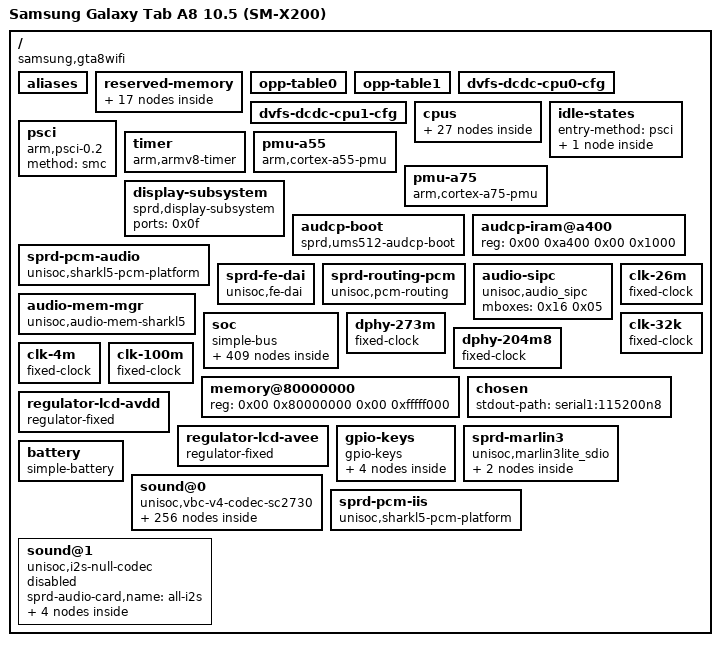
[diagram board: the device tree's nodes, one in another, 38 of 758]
/dts-v1/;

/ {
	interrupt-parent = <0x01>;
	#address-cells = <0x02>;
	#size-cells = <0x02>;
	model = "Samsung Galaxy Tab A8 10.5 (SM-X200)";
	compatible = "samsung,gta8wifi", "sprd,ums512-25c10", "sprd,ums512";
	sprd,sc-id = "ums512 wifionly 1000";

	aliases {
		mmc0 = "/soc/apb@70000000/mmc@1100000";
		mmc1 = "/soc/apb@70000000/mmc@1200000";
		mmc3 = "/soc/apb@70000000/mmc@1400000";
		i2c0 = "/soc/apb@70000000/i2c@300000";
		i2c1 = "/soc/apb@70000000/i2c@400000";
		i2c2 = "/soc/apb@70000000/i2c@500000";
		i2c3 = "/soc/apb@70000000/i2c@600000";
		i2c4 = "/soc/apb@70000000/i2c@700000";
		i2c7 = "/soc/bus@32000000/i2c@60000";
		serial0 = "/soc/apb@70000000/serial@0";
		serial1 = "/soc/apb@70000000/serial@100000";
		spi2 = "/soc/apb@70000000/spi@a00000";
	};

	reserved-memory {
		#address-cells = <0x02>;
		#size-cells = <0x02>;
		ranges;

		audio-mem@87400000 {
			reg = <0x00 0x87400000 0x00 0x400000>;
			no-map;
			phandle = <0x13>;
		};

		smem@88000000 {
			compatible = "shared-dma-pool";
			reg = <0x00 0x88000000 0x00 0x40000>;
			no-map;
			phandle = <0x19>;
		};

		pmsys@88040000 {
			reg = <0x00 0x88040000 0x00 0x2c0000>;
			no-map;
			phandle = <0x18>;
		};

		audiodsp-mem@89000000 {
			reg = <0x00 0x89000000 0x00 0x600000>;
			no-map;
			phandle = <0x12>;
		};

		ddrbist-mem@80000000 {
			reg = <0x00 0x80000000 0x00 0x1000>;
			no-map;
		};

		sysdumpinfo-mem@80001000 {
			reg = <0x00 0x80001000 0x00 0x1000>;
			no-map;
		};

		rebootescrow@81ff0000 {
			reg = <0x00 0x81ff0000 0x00 0x10000>;
			no-map;
		};

		/*
		 * Deduplicated audio-mem@87500000 (subset of audio-mem@87400000)
		 * and sp-ddr-mem@88000000 (union of smem@88000000 + pmsys@88040000).
		 * Reclaimed 196.47 MiB of unused Android carveouts:
		 *   cp-modem@89600000 (85 MiB), hole-mem@8f000000 (11 MiB),
		 *   faceid-mem@efaae000 (5 MiB), vdsp-mem@f09ae000 (55 MiB),
		 *   framebuffer-mem@fd708000 (30.35 MiB), writeback-mem@ff562000 (10.12 MiB).
		 * Validate zero bad pages with tools/ram-scan.py after booting!
		 */

		sipc-mem@87800000 {
			reg = <0x00 0x87800000 0x00 0x800000>;
			no-map;
		};

		sipc-ss-mem@88300000 {
			reg = <0x00 0x88300000 0x00 0x80000>;
			no-map;
		};

		sml-mem@94000000 {
			reg = <0x00 0x94000000 0x00 0x40000>;
			no-map;
		};

		tos-mem@94040000 {
			reg = <0x00 0x94040000 0x00 0x5fc0000>;
			no-map;
		};

		sh-mem@9a000000 {
			reg = <0x00 0x9a000000 0x00 0x100000>;
			no-map;
		};

		ramoops@fff80000 {
			compatible = "ramoops";
			reg = <0x00 0xfff80000 0x00 0x40000>;
			record-size = <0x8000>;
			console-size = <0x8000>;
			pmsg-size = <0x8000>;
			no-map;
		};

		debug-mem@100000000 {
			reg = <0x01 0x00 0x00 0x1000>;
			no-map;
		};

		framebuffer-region@9e000000 {
			compatible = "framebuffer";
			reg = <0x00 0x9e000000 0x00 0x8ca000>;
			iommu-addresses = <0x02 0x9e000000 0x8ca000>;
			no-map;
			phandle = <0xad>;
		};

		/*
		 * Stock wifionly overlay: drm_reserved (secure video). The TEE
		 * firewalls it: writes vanish, reads return zero (measured
		 * 2026-11-10, 0xe32ae000-0xee6adfff). Reserve stock's full size.
		 */
		drm-mem@e32ae000 {
			reg = <0x00 0xe32ae000 0x00 0xc800000>;
			no-map;
		};

		protected-mem@effae000 {
			reg = <0x00 0xeffae000 0x00 0x2000>;
			no-map;
		};
	};

	opp-table0 {
		sprd,hw-dvfs-device = <0x03>;
		cpufreq-cluster-cpumask = <0x3f>;
		transition_delay_us = <0x1f4>;
		operating-points = <0x96000 0xb8a1a 0xbb800 0xb8a1a 0xeadd0 0xb8a1a 0x1174c0 0xb8a1a 0x12c000 0xc042c 0x169d10 0xd59f8 0x177000 0xd9701 0x1a2f20 0xe8b25 0x1bc560 0xf1da1 0x1e8c50 0x100590>;
		phandle = <0x0c>;
	};

	opp-table1 {
		sprd,hw-dvfs-device = <0x03>;
		cpufreq-cluster-cpumask = <0xc0>;
		transition_delay_us = <0x1f4>;
		operating-points = <0x12c000 0xb71b0 0x169d10 0xcf850 0x177000 0xd4670 0x1a94b0 0xe7ef0 0x1c9080 0xf4240 0x1e8c50 0x100590>;
		phandle = <0x0e>;
	};

	dvfs-dcdc-cpu0-cfg {
		pmic-type-num = <0x00>;
		slew-rate = <0x249f>;
		tuning-latency-us = <0x00>;
		phandle = <0x22>;
	};

	dvfs-dcdc-cpu1-cfg {
		third-pmic-used;
		chnl-i2c-used;
		pmic-type-num = <0x02>;
		slew-rate = <0xfa0>;
		tuning-latency-us = <0x00>;
		phandle = <0x23>;
	};

	cpus {
		#address-cells = <0x02>;
		#size-cells = <0x00>;

		cpu-map {

			cluster0 {

				core0 {
					cpu = <0x04>;
				};

				core1 {
					cpu = <0x05>;
				};

				core2 {
					cpu = <0x06>;
				};

				core3 {
					cpu = <0x07>;
				};

				core4 {
					cpu = <0x08>;
				};

				core5 {
					cpu = <0x09>;
				};
			};

			cluster1 {

				core0 {
					cpu = <0x0a>;
				};

				core1 {
					cpu = <0x0b>;
				};
			};
		};

		cpu@0 {
			device_type = "cpu";
			compatible = "arm,cortex-a55";
			reg = <0x00 0x00>;
			cpufreq-data-v1 = <0x0c>;
			enable-method = "psci";
			cpu-idle-states = <0x0d>;
			clock-frequency = <0x6c7aff00>;
			capacity-dmips-mhz = <0x220>;
			dynamic-power-coefficient = <0x66>;
			#cooling-cells = <0x02>;
			phandle = <0x04>;

			thermal-idle {
				#cooling-cells = <0x02>;
				duration-us = <0x2710>;
				exit-latency-us = <0xfa0>;
			};
		};

		cpu@100 {
			device_type = "cpu";
			compatible = "arm,cortex-a55";
			reg = <0x00 0x100>;
			cpufreq-data-v1 = <0x0c>;
			enable-method = "psci";
			cpu-idle-states = <0x0d>;
			clock-frequency = <0x6c7aff00>;
			capacity-dmips-mhz = <0x220>;
			dynamic-power-coefficient = <0x66>;
			#cooling-cells = <0x02>;
			phandle = <0x05>;

			thermal-idle {
				#cooling-cells = <0x02>;
				duration-us = <0x2710>;
				exit-latency-us = <0xfa0>;
			};
		};

		cpu@200 {
			device_type = "cpu";
			compatible = "arm,cortex-a55";
			reg = <0x00 0x200>;
			cpufreq-data-v1 = <0x0c>;
			enable-method = "psci";
			cpu-idle-states = <0x0d>;
			clock-frequency = <0x6c7aff00>;
			capacity-dmips-mhz = <0x220>;
			dynamic-power-coefficient = <0x66>;
			#cooling-cells = <0x02>;
			phandle = <0x06>;

			thermal-idle {
				#cooling-cells = <0x02>;
				duration-us = <0x2710>;
				exit-latency-us = <0xfa0>;
			};
		};

		cpu@300 {
			device_type = "cpu";
			compatible = "arm,cortex-a55";
			reg = <0x00 0x300>;
			cpufreq-data-v1 = <0x0c>;
			enable-method = "psci";
			cpu-idle-states = <0x0d>;
			clock-frequency = <0x6c7aff00>;
			capacity-dmips-mhz = <0x220>;
			dynamic-power-coefficient = <0x66>;
			#cooling-cells = <0x02>;
			phandle = <0x07>;

			thermal-idle {
				#cooling-cells = <0x02>;
				duration-us = <0x2710>;
				exit-latency-us = <0xfa0>;
			};
		};

		cpu@400 {
			device_type = "cpu";
			compatible = "arm,cortex-a55";
			reg = <0x00 0x400>;
			cpufreq-data-v1 = <0x0c>;
			enable-method = "psci";
			cpu-idle-states = <0x0d>;
			clock-frequency = <0x6c7aff00>;
			capacity-dmips-mhz = <0x220>;
			dynamic-power-coefficient = <0x66>;
			#cooling-cells = <0x02>;
			phandle = <0x08>;

			thermal-idle {
				#cooling-cells = <0x02>;
				duration-us = <0x2710>;
				exit-latency-us = <0xfa0>;
			};
		};

		cpu@500 {
			device_type = "cpu";
			compatible = "arm,cortex-a55";
			reg = <0x00 0x500>;
			cpufreq-data-v1 = <0x0c>;
			enable-method = "psci";
			cpu-idle-states = <0x0d>;
			clock-frequency = <0x6c7aff00>;
			capacity-dmips-mhz = <0x220>;
			dynamic-power-coefficient = <0x66>;
			#cooling-cells = <0x02>;
			phandle = <0x09>;

			thermal-idle {
				#cooling-cells = <0x02>;
				duration-us = <0x2710>;
				exit-latency-us = <0xfa0>;
			};
		};

		cpu@600 {
			device_type = "cpu";
			compatible = "arm,cortex-a75";
			reg = <0x00 0x600>;
			cpufreq-data-v1 = <0x0e>;
			enable-method = "psci";
			cpu-idle-states = <0x0d>;
			clock-frequency = <0x6c7aff00>;
			capacity-dmips-mhz = <0x400>;
			dynamic-power-coefficient = <0x1f5>;
			#cooling-cells = <0x02>;
			phandle = <0x0a>;

			thermal-idle {
				#cooling-cells = <0x02>;
				duration-us = <0x2710>;
				exit-latency-us = <0xfa0>;
			};
		};

		cpu@700 {
			device_type = "cpu";
			compatible = "arm,cortex-a75";
			reg = <0x00 0x700>;
			cpufreq-data-v1 = <0x0e>;
			enable-method = "psci";
			cpu-idle-states = <0x0d>;
			clock-frequency = <0x6c7aff00>;
			capacity-dmips-mhz = <0x400>;
			dynamic-power-coefficient = <0x1f5>;
			#cooling-cells = <0x02>;
			phandle = <0x0b>;

			thermal-idle {
				#cooling-cells = <0x02>;
				duration-us = <0x2710>;
				exit-latency-us = <0xfa0>;
			};
		};
	};

	idle-states {
		entry-method = "psci";

		cpu-pd {
			compatible = "arm,idle-state";
			entry-latency-us = <0xfa0>;
			exit-latency-us = <0xfa0>;
			min-residency-us = <0x2710>;
			local-timer-stop;
			arm,psci-suspend-param = <0x10000>;
			phandle = <0x0d>;
		};
	};

	psci {
		compatible = "arm,psci-0.2";
		method = "smc";
	};

	timer {
		compatible = "arm,armv8-timer";
		interrupts = <0x01 0x0d 0x04 0x01 0x0e 0x04 0x01 0x0b 0x04 0x01 0x0a 0x04>;
	};

	pmu-a55 {
		compatible = "arm,cortex-a55-pmu";
		interrupts = <0x00 0x70 0x04 0x00 0x71 0x04 0x00 0x72 0x04 0x00 0x73 0x04 0x00 0x74 0x04 0x00 0x75 0x04>;
		interrupt-affinity = <0x04 0x05 0x06 0x07 0x08 0x09>;
	};

	pmu-a75 {
		compatible = "arm,cortex-a75-pmu";
		interrupts = <0x00 0x76 0x04 0x00 0x77 0x04>;
		interrupt-affinity = <0x0a 0x0b>;
	};

	display-subsystem {
		compatible = "sprd,display-subsystem";
		ports = <0x0f>;
		status = "okay";
	};

	audcp-boot {
		compatible = "sprd,ums512-audcp-boot";
		dsp-reboot-mode = <0x00>;
		sysshutdown = <0x10 0x60 0x2000000>;
		coreshutdown = <0x10 0x5c 0x1000000>;
		deepsleep = <0x10 0xcc 0x80000>;
		corereset = <0x10 0xb0 0x400>;
		sysreset = <0x10 0xb0 0x200>;
		reset_sel = <0x10 0x7a4 0xff>;
		sysstatus = <0x10 0xb8 0xff000000>;
		corestatus = <0x10 0x10c 0xff>;
		sleepstatus = <0x10 0xd4 0xf000>;
		bootprotect = <0x11 0x78 0xffff>;
		bootvector = <0x11 0x140 0xffffffff>;
		bootaddress_sel = <0x11 0x144 0x01>;
		accessenable = <0x11 0x14c 0x20>;
		memory-region = <0x12 0x13>;
		sprd,audcp-aon-iram = <0x14>;
		#power-domain-cells = <0x00>;
		status = "okay";
		phandle = <0x36>;
	};

	audcp-iram@a400 {
		reg = <0x00 0xa400 0x00 0x1000>;
		phandle = <0x14>;
	};

	sprd-pcm-audio {
		compatible = "unisoc,sharkl5-pcm-platform", "unisoc,sharkl5pro-pcm-platform";
		#sound-dai-cells = <0x00>;
		dmas = <0x15 0x01 0x15 0x02 0x15 0x03 0x15 0x04 0x15 0x11 0x15 0x12 0x15 0x0f 0x15 0x10 0x15 0x0e 0x15 0x08 0x15 0x0c 0x15 0x09 0x15 0x0d 0x15 0x08 0x15 0x0b 0x15 0x06 0x15 0x0e 0x15 0x0e 0x15 0x0c 0x15 0x06 0x15 0x07 0x15 0x14>;
		dma-names = "normal_p_l", "normal_p_r", "normal_c_l", "normal_c_r", "normal23_p_l", "normal23_p_r", "normal23_c_l", "normal23_c_r", "dspcap_c", "a2dppcm_p", "voice_c", "fast_p", "loop_c", "loop_p", "voip_c", "voip_p", "dspfmcap_c", "dspbtscocap_c", "recognise_c", "voice_pcm_p", "hifi_p", "hifi_fast_p";
		phandle = <0xbb>;
	};

	sprd-fe-dai {
		compatible = "unisoc,fe-dai";
		#sound-dai-cells = <0x01>;
		phandle = <0xbc>;
	};

	sprd-routing-pcm {
		compatible = "unisoc,pcm-routing";
		#sound-dai-cells = <0x00>;
		phandle = <0xbd>;
	};

	audio-sipc {
		compatible = "unisoc,audio_sipc";
		mboxes = <0x16 0x05>;
	};

	audio-mem-mgr {
		compatible = "unisoc,audio-mem-sharkl5", "unisoc,audio-mem-sharkl5pro";
		memory-region = <0x13 0x12>;
		ddr32-ap-dsp-map-offset = <0x00>;
		sprd,ddr32-dma = <0x87400000 0x300000>;
		sprd,ddr32-dspmemdump = <0x87700000 0x80000>;
		sprd,cmdaddr = <0x87780000 0x400>;
		sprd,smsg-addr = <0x87780400 0xa10>;
		sprd,shmaddr-aud-str = <0x87780e10 0x400>;
		sprd,shmaddr-dsp-vbc = <0x87781210 0x1400>;
		sprd,shmaddr-nxp = <0x87782610 0x400>;
		sprd,shmaddr-dsp-smartpa = <0x87782a10 0x1000>;
		sprd,shmaddr-reg-dump = <0x87783a10 0x400>;
		sprd,iram-ap-base = <0x33800000>;
		sprd,iram-dsp-base = <0x1800000>;
		sprd,offload-addr = <0x33800000 0x5c00>;
		sprd,normal-captue-linklilst-node1 = <0x33805e00 0x200>;
		sprd,normal-captue-data = <0x33806000 0x1e00>;
		sprd,normal-captue-linklilst-node2 = <0x33807e00 0x200>;
		sprd,audcp-aon-iram = <0x14>;
	};

	soc {
		compatible = "simple-bus";
		#address-cells = <0x02>;
		#size-cells = <0x02>;
		ranges;

		pmsys@800000 {
			compatible = "sprd,ums512-pmsys";
			/*
			 * LK 0x9f00c880 contract: sprd,name="pmic" + child cproc,name="pm_sys".
			 * Keep disabled until Trusty TA com.android.trusty.kernelbootcp
			 * (/dev/trusty-ipc-dev0) is wired: TrustOS locks AON_APB 0x327d008c
			 * (SP CM4 core reset) against non-secure EL1 writes.
			 */
			sprd,name = "pmic";
			status = "disabled";
			reg = <0x00 0x800000 0x00 0x1000>;
			dma-ranges = <0x18000000 0x00 0x88000000 0x8000000>;
			#address-cells = <0x01>;
			#size-cells = <0x01>;
			ranges = <0x88040000 0x00 0x88040000 0x200000>;
			sprd,syscon-aon-apb = <0x11>;
			sprd,syscon-pmu-apb = <0x10>;
			resets = <0x17 0x08>;
			memory-region = <0x18>;
			firmware-name = "sprd/pm_bootcode.bin", "sprd/pm_sys.bin";

			pm-sys@88040000 {
				cproc,name = "pm_sys";
				reg = <0x88040000 0x200000>;
			};

			sipc {
				#address-cells = <0x01>;
				#size-cells = <0x00>;
				label = "pmsys";
				mboxes = <0x16 0x01 0x16 0x06>;
				memory-region = <0x19>;

				channel@4 {
					reg = <0x04>;
					sprd,channel-type = "sbuf";
					sprd,channel-name = "pm_shub";
					#address-cells = <0x01>;
					#size-cells = <0x01>;
					sprd,num-buffers = <0x02>;
					sprd,tx-buf-size = <0x800>;
					sprd,rx-buf-size = <0xb00>;

					rpmsg@0 {
						compatible = "samsung,sprd-shub";
						reg = <0x00 0x00>;
						sprd,channel-name = "shub_main";
					};

					rpmsg@1 {
						compatible = "samsung,sprd-shub";
						reg = <0x01 0x01>;
						sprd,channel-name = "shub_nowakeup";
					};
				};

				channel@5 {
					reg = <0x05>;
					sprd,channel-type = "sbuf";
					sprd,channel-name = "slog_pm";
					#address-cells = <0x01>;
					#size-cells = <0x01>;
					sprd,tx-buf-size = <0x00>;
					sprd,rx-buf-size = <0x500>;

					rpmsg@0 {
						reg = <0x00 0x00>;
						sprd,channel-name = "slog_pm";
					};
				};

				channel@6 {
					reg = <0x06>;
					sprd,channel-type = "sbuf";
					sprd,channel-name = "sctl_pm";
					#address-cells = <0x01>;
					#size-cells = <0x01>;
					sprd,tx-buf-size = <0x20>;
					sprd,rx-buf-size = <0x40>;

					rpmsg@0 {
						reg = <0x00 0x00>;
						sprd,channel-name = "sctl_pm";
					};
				};

				channel@29 {
					reg = <0x29>;
					sprd,channel-type = "sbuf";
					sprd,channel-name = "stime_pm";
					#address-cells = <0x01>;
					#size-cells = <0x01>;
					sprd,tx-buf-size = <0x80>;
					sprd,rx-buf-size = <0x40>;

					rpmsg@0 {
						reg = <0x00 0x00>;
						sprd,channel-name = "stime_pm";
					};
				};

				channel@16 {
					reg = <0x16>;
					sprd,channel-type = "dfs";
					sprd,channel-name = "pm_ctrl";
				};
			};
		};

		interrupt-controller@12000000 {
			compatible = "arm,gic-v3";
			reg = <0x00 0x12000000 0x00 0x20000 0x00 0x12040000 0x00 0x100000>;
			#interrupt-cells = <0x03>;
			#address-cells = <0x02>;
			#size-cells = <0x02>;
			ranges;
			redistributor-stride = <0x00 0x20000>;
			#redistributor-regions = <0x01>;
			interrupt-controller;
			interrupts = <0x01 0x09 0x04>;
			phandle = <0x01>;
		};

		syscon@20100000 {
			compatible = "sprd,ums512-glbregs", "syscon", "simple-mfd";
			reg = <0x00 0x20100000 0x00 0x4000>;
			#address-cells = <0x01>;
			#size-cells = <0x01>;
			ranges = <0x00 0x00 0x20100000 0x4000>;
			phandle = <0xae>;

			clock-controller@0 {
				compatible = "sprd,ums512-apahb-gate";
				reg = <0x00 0x3000>;
				clocks = <0x1a>;
				clock-names = "ext-26m";
				#clock-cells = <0x01>;
				phandle = <0x48>;
			};
		};

		syscon@31050000 {
			compatible = "sprd,ums512-glbregs", "syscon", "simple-mfd";
			reg = <0x00 0x31050000 0x00 0x9000>;
		};

		efuse@32240000 {
			compatible = "sprd,ums312-efuse";
			reg = <0x00 0x32240000 0x00 0x10000>;
			clock-names = "enable";
			clocks = <0x1b 0x10>;
			hwlocks = <0x1c 0x08>;

			nvmem-layout {
				compatible = "fixed-layout";
				#address-cells = <0x01>;
				#size-cells = <0x01>;

				uid-start@5c {
					reg = <0x5c 0x04>;
					phandle = <0xb9>;
				};

				uid-end@58 {
					reg = <0x58 0x04>;
					phandle = <0xba>;
				};

				thm0-sign@38 {
					reg = <0x38 0x01>;
					bits = <0x00 0x01>;
					phandle = <0x8a>;
				};

				thm0-ratio@38 {
					reg = <0x38 0x01>;
					bits = <0x01 0x07>;
					phandle = <0x8b>;
				};

				thm0-sen0@39 {
					reg = <0x39 0x01>;
					bits = <0x00 0x08>;
					phandle = <0x8c>;
				};

				thm0-sen1@41 {
					reg = <0x41 0x01>;
					bits = <0x00 0x08>;
					phandle = <0x8d>;
				};

				thm0-sen2@40 {
					reg = <0x40 0x01>;
					bits = <0x00 0x08>;
					phandle = <0x8e>;
				};

				thm0-sen3@43 {
					reg = <0x43 0x01>;
					bits = <0x00 0x08>;
					phandle = <0x8f>;
				};

				thm0-sen4@42 {
					reg = <0x42 0x01>;
					bits = <0x00 0x08>;
					phandle = <0x90>;
				};

				thm1-sign@3c {
					reg = <0x3c 0x01>;
					bits = <0x00 0x01>;
					phandle = <0x91>;
				};

				thm1-ratio@3c {
					reg = <0x3c 0x01>;
					bits = <0x01 0x07>;
					phandle = <0x92>;
				};

				thm1-sen0@3d {
					reg = <0x3d 0x01>;
					bits = <0x00 0x08>;
					phandle = <0x93>;
				};

				thm1-sen1@2f {
					reg = <0x2f 0x01>;
					bits = <0x00 0x08>;
					phandle = <0x94>;
				};

				thm1-sen2@2e {
					reg = <0x2e 0x01>;
					bits = <0x00 0x08>;
					phandle = <0x95>;
				};

				thm1-sen3@29 {
					reg = <0x29 0x01>;
					bits = <0x00 0x08>;
					phandle = <0x96>;
				};

				thm1-sen4@28 {
					reg = <0x28 0x01>;
					bits = <0x00 0x08>;
					phandle = <0x97>;
				};

				thm1-sen5@2b {
					reg = <0x2b 0x01>;
					bits = <0x00 0x08>;
					phandle = <0x98>;
				};

				thm2-sign@3e {
					reg = <0x3e 0x01>;
					bits = <0x00 0x01>;
					phandle = <0x99>;
				};

				thm2-ratio@3e {
					reg = <0x3e 0x01>;
					bits = <0x01 0x07>;
					phandle = <0x9a>;
				};

				thm2-sen0@3f {
					reg = <0x3f 0x01>;
					bits = <0x00 0x08>;
					phandle = <0x9b>;
				};
			};
		};

		syscon@322a0000 {
			compatible = "sprd,sharkl5pro-topdvfs-dev", "sprd,topdvfs-dev", "sprd,sharkl5pro-topdvfs", "sprd,ums512-glbregs", "syscon";
			reg = <0x00 0x322a0000 0x00 0x8000>;
			sprd,syscon-enable = <0x11>;
			module-enable-cfg = <0x04 0x07>;
			sprd,topdvfs-sysctrl = <0x1d>;
			cpu-dcdc-cells = <0x1e 0x1f>;
			device-dcdc-cells = <0x20 0x21>;
			phandle = <0x1d>;

			dcdc-cpu0 {
				dcdc-cpu-dvfs-cfg = <0x22>;
				phandle = <0x1e>;
			};

			dcdc-cpu1 {
				dcdc-cpu-dvfs-cfg = <0x23>;
				phandle = <0x1f>;
			};

			dcdc-mm {
				dcdc-dvfs-enable = <0x18 0x14 0x01>;
				dcdc-judge-vol-sw = <0x18 0x01 0x07 0x02>;
				dcdc-subsys-cells = <0x24 0x25 0x26>;
				phandle = <0x20>;

				audcp-sys {
					dcdc-subsys-tune-enable = <0x150 0x05 0x00>;
					phandle = <0x24>;
				};

				gpu-sys {
					dcdc-subsys-tune-enable = <0x150 0x01 0x01>;
					phandle = <0x25>;
				};

				mm-sys {
					dcdc-subsys-tune-enable = <0x150 0x02 0x00>;
					phandle = <0x26>;
				};
			};

			dcdc-modem {
				dcdc-dvfs-enable = <0x3c 0x14 0x01>;
				dcdc-judge-vol-sw = <0x3c 0x01 0x07 0x02>;
				dcdc-subsys-cells = <0x27 0x28 0x29>;
				phandle = <0x21>;

				pubcp-sys {
					dcdc-subsys-tune-enable = <0x150 0x04 0x00>;
					phandle = <0x27>;
				};

				wtlcp-sys {
					dcdc-subsys-tune-enable = <0x150 0x03 0x00>;
					phandle = <0x28>;
				};

				ap-sys {
					dcdc-subsys-tune-enable = <0x150 0x00 0x01>;
					phandle = <0x29>;
				};
			};
		};

		hardware-dvfs-platform {
			compatible = "sprd,hardware-cpufreq";
		};

		cpudvfs-dev@322a8000 {
			compatible = "sprd,sharkl5pro-cpudvfs";
			reg = <0x00 0x322a8000 0x00 0x1000>;
			enable-syscon = <0x11 0x04 0x80>;
			topdvfs-controller = <0x1d>;
			host-cluster-cells = <0x2a 0x2b>;
			slave-cluster-cells = <0x2c 0x2d 0x2e>;
			mpll-cells = <0x2f 0x30 0x31>;
			status = "okay";
			phandle = <0x03>;

			lit-core-cluster {
				belong-dcdc-cell = <0x00>;
				lit_core_cluster_tbl = <0x00 0x00 0x00 0x00 0x00 0x00 0x00 0x01 0x01 0x00 0x01 0x01 0x01 0x00 0x02 0x01 0x00 0x02 0x01 0x01 0x00 0x03 0x00 0x00 0x02 0x01 0x01 0x00 0x03 0x00 0x00 0x03 0x01 0x01 0x01 0x01 0x00 0x01 0x04 0x01 0x01 0x00 0x03 0x00 0x02 0x05 0x04 0x04 0x02 0x02 0x00 0x03 0x06 0x04 0x04 0x00 0x03 0x00 0x04 0x07 0x04 0x05 0x03 0x03 0x00 0x05 0x08 0x04 0x05 0x04 0x03 0x00 0x06 0x09 0x05 0x05 0x05>;
				phandle = <0x2a>;
			};

			big-core-cluster {
				belong-dcdc-cell = <0x01>;
				big_core_cluster_tbl = <0x00 0x00 0x00 0x00 0x00 0x00 0x00 0x01 0x00 0x00 0x03 0x01 0x01 0x00 0x03 0x00 0x01 0x05 0x04 0x04 0x00 0x02 0x00 0x02 0x06 0x04 0x04 0x00 0x03 0x00 0x03 0x07 0x04 0x05 0x01 0x03 0x00 0x04 0x08 0x04 0x05 0x03 0x03 0x00 0x05 0x09 0x05 0x05 0x04>;
				phandle = <0x2b>;
			};

			scu-cluster {
				belong-dcdc-cell = <0x00>;
				scu_cluster_tbl = <0x00 0x00 0x00 0x00 0x00 0x03 0x00 0x00 0x01 0x00 0x03 0x00 0x00 0x01 0x01 0x01 0x00 0x00 0x01 0x00 0x03 0x00 0x01 0x01 0x02 0x03 0x00 0x02 0x01 0x03 0x03 0x00 0x03 0x01 0x04 0x03 0x00 0x04 0x01 0x05 0x03 0x00 0x05 0x01 0x06 0x03 0x00 0x06 0x01 0x07>;
				phandle = <0x2c>;
			};

			periph-cluster {
				belong-dcdc-cell = <0x00>;
				periph_cluster_tbl = <0x00 0x00 0x00 0x01 0x00 0x00 0x02 0x01 0x02 0x03 0x01 0x02 0x02 0x00 0x02 0x03 0x00 0x06>;
				phandle = <0x2d>;
			};

			gic-cluster {
				belong-dcdc-cell = <0x00>;
				gic_cluster_tbl = <0x00 0x00 0x00 0x01 0x00 0x00 0x02 0x01 0x02 0x03 0x01 0x02 0x02 0x00 0x02 0x03 0x00 0x02>;
				phandle = <0x2e>;
			};

			mpll-ananke {
				mpll-sel-syscon = <0x32 0x98 0xd0>;
				phandle = <0x2f>;
			};

			mpll-prometheus {
				mpll-sel-syscon = <0x33 0x44 0xd0>;
				phandle = <0x30>;
			};

			mpll-scu {
				mpll-sel-syscon = <0x32 0xdc 0x68>;
				phandle = <0x31>;
			};
		};

		syscon@32310000 {
			compatible = "sprd,ums512-glbregs", "syscon", "simple-mfd";
			reg = <0x00 0x32310000 0x00 0x1000>;
		};

		syscon@32320000 {
			compatible = "sprd,ums512-glbregs", "syscon", "simple-mfd";
			reg = <0x00 0x32320000 0x00 0x1000>;
		};

		syscon@32330000 {
			compatible = "sprd,ums512-glbregs", "syscon", "simple-mfd";
			reg = <0x00 0x32330000 0x00 0x1000>;
		};

		syscon@32340000 {
			compatible = "sprd,ums512-glbregs", "syscon", "simple-mfd";
			reg = <0x00 0x32340000 0x00 0x1000>;
		};

		syscon@32350000 {
			compatible = "sprd,ums512-glbregs", "syscon", "simple-mfd";
			reg = <0x00 0x32350000 0x00 0x1000>;
		};

		syscon@32360000 {
			compatible = "sprd,ums512-glbregs", "syscon", "simple-mfd";
			reg = <0x00 0x32360000 0x00 0x1000>;
		};

		syscon@32390000 {
			compatible = "sprd,ums512-glbregs", "syscon", "simple-mfd";
			reg = <0x00 0x32390000 0x00 0x3000>;
			#address-cells = <0x01>;
			#size-cells = <0x01>;
			ranges = <0x00 0x00 0x32390000 0x3000>;

			clock-controller@0 {
				compatible = "sprd,ums512-g0-pll";
				reg = <0x00 0x100>;
				#clock-cells = <0x01>;
			};
		};

		syscon@323b0000 {
			compatible = "sprd,ums512-glbregs", "syscon", "simple-mfd";
			reg = <0x00 0x323b0000 0x00 0x3000>;
			#address-cells = <0x01>;
			#size-cells = <0x01>;
			ranges = <0x00 0x00 0x323b0000 0x3000>;
			phandle = <0x33>;

			clock-controller@0 {
				compatible = "sprd,ums512-g2-pll";
				reg = <0x00 0x100>;
				#clock-cells = <0x01>;
			};

			phy@100 {
				compatible = "sprd,ums512-hsphy";
				reg = <0x100 0x2000>;
				sprd,syscon-aon-apb = <0x11>;
				#phy-cells = <0x00>;
				status = "okay";
				phy-supply = <0x34>;
				phandle = <0x9c>;
			};
		};

		syscon@323c0000 {
			compatible = "sprd,ums512-glbregs", "syscon", "simple-mfd";
			reg = <0x00 0x323c0000 0x00 0x3000>;
			#address-cells = <0x01>;
			#size-cells = <0x01>;
			ranges = <0x00 0x00 0x323c0000 0x3000>;
			phandle = <0x32>;

			clock-controller@0 {
				compatible = "sprd,ums512-g3-pll";
				reg = <0x00 0x3000>;
				clocks = <0x1a>;
				clock-names = "ext-26m";
				#clock-cells = <0x01>;
				phandle = <0x72>;
			};
		};

		syscon@323e0000 {
			compatible = "sprd,ums512-glbregs", "syscon", "simple-mfd";
			reg = <0x00 0x323e0000 0x00 0x3000>;
			#address-cells = <0x01>;
			#size-cells = <0x01>;
			ranges = <0x00 0x00 0x323e0000 0x3000>;

			clock-controller@0 {
				compatible = "sprd,ums512-gc-pll";
				reg = <0x00 0x100>;
				clocks = <0x1a>;
				clock-names = "ext-26m";
				#clock-cells = <0x01>;
				phandle = <0x45>;
			};
		};

		syscon@323f0000 {
			compatible = "sprd,ums512-glbregs", "syscon", "simple-mfd";
			reg = <0x00 0x323f0000 0x00 0x3000>;
		};

		syscon@327d0000 {
			compatible = "sprd,ums512-glbregs", "syscon", "simple-mfd";
			reg = <0x00 0x327d0000 0x00 0x3000>;
			#address-cells = <0x01>;
			#size-cells = <0x01>;
			ranges = <0x00 0x00 0x327d0000 0x3000>;
			phandle = <0x11>;

			clock-controller@0 {
				compatible = "sprd,ums512-aon-gate";
				reg = <0x00 0x3000>;
				clocks = <0x1a>;
				clock-names = "ext-26m";
				#clock-cells = <0x01>;
				phandle = <0x1b>;
			};
		};

		syscon@327e0000 {
			compatible = "sprd,ums512-glbregs", "syscon", "simple-mfd";
			reg = <0x00 0x327e0000 0x00 0x3000>;
			#address-cells = <0x01>;
			#size-cells = <0x01>;
			ranges = <0x00 0x00 0x327e0000 0x3000>;
			phandle = <0x10>;

			clock-controller@0 {
				compatible = "sprd,ums512-pmu-gate";
				reg = <0x00 0x3000>;
				clocks = <0x1a>;
				clock-names = "ext-26m";
				#clock-cells = <0x01>;
				#reset-cells = <0x01>;
				phandle = <0x17>;
			};

			power-controller {
				compatible = "sprd,ums512-power-controller";
				#address-cells = <0x01>;
				#size-cells = <0x00>;
				#power-domain-cells = <0x01>;
				phandle = <0x43>;

				power-domain@10 {
					reg = <0x0a>;
					clocks = <0x1b 0x08>;
					#power-domain-cells = <0x00>;
				};

				power-domain@13 {
					reg = <0x0d>;
					clocks = <0x1b 0x07>;
					#power-domain-cells = <0x00>;
				};

				power-domain@24 {
					reg = <0x18>;
					#power-domain-cells = <0x00>;
				};
			};
		};

		gpio@32000000 {
			compatible = "sprd,sharkl5pro-eic-debounce", "sprd,sc9860-eic-debounce";
			reg = <0x00 0x32020000 0x00 0x80 0x00 0x32030000 0x00 0x80 0x00 0x32230000 0x00 0x80 0x00 0x32270000 0x00 0x80>;
			gpio-controller;
			#gpio-cells = <0x02>;
			interrupt-controller;
			#interrupt-cells = <0x02>;
			interrupts = <0x00 0x48 0x04>;
		};

		gpio@32000080 {
			compatible = "sprd,sharkl5pro-eic-latch", "sprd,sc9860-eic-latch";
			reg = <0x00 0x32020080 0x00 0x20 0x00 0x32030080 0x00 0x20 0x00 0x32230080 0x00 0x20 0x00 0x32270080 0x00 0x20>;
			gpio-controller;
			#gpio-cells = <0x02>;
			interrupt-controller;
			#interrupt-cells = <0x02>;
			interrupts = <0x00 0x48 0x04>;
		};

		gpio@320000a0 {
			compatible = "sprd,sharkl5pro-eic-async", "sprd,sc9860-eic-async";
			reg = <0x00 0x320200a0 0x00 0x20 0x00 0x320300a0 0x00 0x20 0x00 0x322300a0 0x00 0x20 0x00 0x322700a0 0x00 0x20>;
			gpio-controller;
			#gpio-cells = <0x02>;
			interrupt-controller;
			#interrupt-cells = <0x02>;
			interrupts = <0x00 0x48 0x04>;
			phandle = <0xc8>;
		};

		gpio@320000c0 {
			compatible = "sprd,sharkl5pro-eic-sync", "sprd,sc9860-eic-sync";
			reg = <0x00 0x320200c0 0x00 0x20 0x00 0x320300c0 0x00 0x20 0x00 0x322300c0 0x00 0x20 0x00 0x322700c0 0x00 0x20>;
			gpio-controller;
			#gpio-cells = <0x02>;
			interrupt-controller;
			#interrupt-cells = <0x02>;
			interrupts = <0x00 0x48 0x04>;
			phandle = <0x73>;
		};

		syscon@3350d000 {
			compatible = "sprd,ums512-glbregs", "syscon", "simple-mfd";
			reg = <0x00 0x3350d000 0x00 0x1000>;
			#address-cells = <0x01>;
			#size-cells = <0x01>;
			ranges = <0x00 0x00 0x3350d000 0x1000>;

			clock-controller@0 {
				compatible = "sprd,ums512-audcpapb-gate";
				reg = <0x00 0x300>;
				#clock-cells = <0x01>;
			};
		};

		syscon@335e0000 {
			compatible = "sprd,ums512-glbregs", "syscon", "simple-mfd";
			reg = <0x00 0x335e0000 0x00 0x1000>;
			#address-cells = <0x01>;
			#size-cells = <0x01>;
			ranges = <0x00 0x00 0x335e0000 0x1000>;
			phandle = <0x35>;

			clock-controller@0 {
				compatible = "sprd,ums512-audcpahb-gate";
				reg = <0x00 0x300>;
				#clock-cells = <0x01>;
				phandle = <0x42>;
			};
		};

		mailbox@320a0000 {
			compatible = "sprd,ums512-mailbox";
			reg = <0x00 0x320a0000 0x00 0x8000 0x00 0x320a8000 0x00 0x8000>;
			clocks = <0x1b 0x12>;
			clock-names = "enable";
			interrupts = <0x00 0x52 0x04 0x00 0x53 0x04 0x00 0x54 0x04>;
			interrupt-names = "inbox", "outbox", "supp-outbox";
			#mbox-cells = <0x01>;
			status = "okay";
			phandle = <0x16>;
		};

		agcp {
			compatible = "simple-bus";
			#address-cells = <0x02>;
			#size-cells = <0x02>;
			ranges;

			vbc@33480000 {
				compatible = "unisoc,sharkl5-vbc", "unisoc,sharkl5pro-vbc";
				#sound-dai-cells = <0x01>;
				reg = <0x00 0x33480000 0x00 0x1000>;
				sprd,syscon-agcp-ahb = <0x35>;
				sprd,vbc-phy-offset = <0x32000000>;
				power-domains = <0x36>;
				pinctrl-names = "vbc_iis3_0", "vbc_iism0_0", "vbc_iis_to_pad", "vbc_iis_to_aon_usb", "vbc_iism0_1", "vbc_iism0_3", "vbc_iis0_3", "vbc_iis1_3", "vbc_iis2_3", "vbc_iis3_3", "ap_iis0_3";
				pinctrl-0 = <0x37>;
				pinctrl-1 = <0x38>;
				pinctrl-2 = <0x39>;
				pinctrl-3 = <0x3a>;
				pinctrl-4 = <0x3b>;
				pinctrl-5 = <0x3c>;
				pinctrl-6 = <0x3d>;
				pinctrl-7 = <0x3e>;
				pinctrl-8 = <0x3f>;
				pinctrl-9 = <0x40>;
				pinctrl-10 = <0x41>;
				phandle = <0xbe>;
			};

			mcdt@33490000 {
				compatible = "unisoc,sharkl5-mcdt", "unisoc,sharkl5pro-mcdt";
				reg = <0x00 0x33490000 0x00 0x170>;
				interrupts = <0x00 0xb6 0x04>;
				power-domains = <0x36>;
				sprd,ap-addr-offset = <0x32000000>;
				sprd,syscon-agcp-ahb = <0x35>;
			};

			dma-controller@33580000 {
				compatible = "sprd,sharkl5pro-dma", "sprd,sc9860-dma";
				reg = <0x00 0x33580000 0x00 0x4000>;
				interrupts = <0x00 0xb5 0x04>;
				power-domains = <0x36>;
				#dma-cells = <0x01>;
				dma-channels = <0x20>;
				clock-names = "enable", "ashb_eb";
				clocks = <0x42 0x05 0x42 0x0c>;
				phandle = <0x15>;
			};

			audio-codec@33750000 {
				compatible = "unisoc,audio-codec-dig-agcp";
				reg = <0x00 0x33750000 0x00 0x1000>;
				power-domains = <0x36>;
				sprd,syscon-agcp-ahb = <0x35>;
				phandle = <0x88>;
			};

			agdsp-access {
				compatible = "unisoc,agdsp-access";
				sprd,syscon-agcp-ahb = <0x11>;
				sprd,syscon-pmu-apb = <0x10>;
				audcp_pmu_sleep_ctrl = <0x10 0xcc 0x20>;
				audcp_pmu_slp_status = <0x10 0xd4 0xf000>;
				audcp_pmu_pwr_status4 = <0x10 0xb8 0xff000000>;
				audcp_pmu_pwr_status3 = <0x10 0x10c 0xff>;
				ap_access_ena = <0x11 0x14c 0x20>;
				sprd,ddr-addr-offset = <0x00>;
				sprd,auto_agcp_access = <0x00>;
			};
		};

		syscon@60100000 {
			compatible = "sprd,ums512-glbregs", "syscon", "simple-mfd";
			reg = <0x00 0x60100000 0x00 0x3000>;
			#address-cells = <0x01>;
			#size-cells = <0x01>;
			ranges = <0x00 0x00 0x60100000 0x3000>;
			phandle = <0xc9>;

			clock-controller@0 {
				compatible = "sprd,ums512-gpu-clk";
				clocks = <0x1a>;
				clock-names = "ext-26m";
				reg = <0x00 0x100>;
				power-domains = <0x43 0x0a>;
				#clock-cells = <0x01>;
				#reset-cells = <0x01>;
				phandle = <0x44>;
			};
		};

		syscon@60110000 {
			compatible = "sprd,ums512-glbregs", "syscon", "simple-mfd";
			reg = <0x00 0x60110000 0x00 0x3000>;
		};

		gpu@60000000 {
			compatible = "sprd,ums512-mali", "arm,mali-bifrost";
			reg = <0x00 0x60000000 0x00 0x100000>;
			interrupts = <0x00 0x3c 0x04 0x00 0x3c 0x04 0x00 0x3c 0x04>;
			interrupt-names = "job", "mmu", "gpu";
			clocks = <0x44 0x01 0x44 0x00 0x44 0x02 0x44 0x04 0x44 0x03>;
			clock-names = "core", "gpu", "mem", "bus", "mem_clk";
			assigned-clocks = <0x45 0x1d>;
			assigned-clock-rates = <0x32a9f880>;
			/* Stock mali_gondul.ko /qos/qos@0: gpu_qos_sel=1 (bit 16) + arqos=6/awqos=6/thresh=f/f -> 0x1ff66 */
			sprd,gpu-qos-syscon = <0xc9 0x10 0x0001ff66>;
			power-domains = <0x43 0x0a>;
			resets = <0x44 0x00>;
			operating-points-v2 = <0x46>;
			#cooling-cells = <0x02>;
			status = "okay";
			mali-supply = <0x47>;
			phandle = <0xa6>;
		};

		opp-table-gpu {
			compatible = "operating-points-v2";
			phandle = <0x46>;

			opp-384000000 {
				opp-hz = <0x00 0x16e36000>;
				opp-microvolt = <0xaae60>;
			};

			opp-512000000 {
				opp-hz = <0x00 0x1e848000>;
				opp-microvolt = <0xb71b0>;
			};

			opp-614400000 {
				opp-hz = <0x00 0x249f0000>;
				opp-microvolt = <0xb71b0>;
			};

			opp-768000000 {
				opp-hz = <0x00 0x2dc6c000>;
				opp-microvolt = "", "\f5";
			};

			opp-850000000 {
				opp-hz = <0x00 0x32a9f880>;
				opp-microvolt = "", "\f5";
			};
		};

		syscon@62200000 {
			compatible = "sprd,ums512-glbregs", "syscon", "simple-mfd";
			reg = <0x00 0x62200000 0x00 0x3000>;
			#address-cells = <0x01>;
			#size-cells = <0x01>;
			ranges = <0x00 0x00 0x62200000 0x3000>;

			clock-controller@0 {
				compatible = "sprd,ums512-mm-gate-clk";
				reg = <0x00 0x3000>;
				power-domains = <0x43 0x0d>;
				#clock-cells = <0x01>;
				phandle = <0x4e>;
			};
		};

		/*
		 * AP DVFS block: selects the DPU core clock (work index at 0x124, see
		 * the dpu node). Stock: apsys-dvfs@71700000, "sprd,hwdvfs-apsys-sharkl5pro".
		 */
		syscon@71700000 {
			compatible = "syscon";
			reg = <0x00 0x71700000 0x00 0x160>;
			phandle = <0xc7>;
		};

		syscon@71000000 {
			compatible = "sprd,ums512-glbregs", "syscon", "simple-mfd";
			reg = <0x00 0x71000000 0x00 0x3000>;
			#address-cells = <0x01>;
			#size-cells = <0x01>;
			ranges = <0x00 0x00 0x71000000 0x3000>;
			phandle = <0x49>;

			clock-controller@0 {
				compatible = "sprd,ums512-apapb-gate";
				reg = <0x00 0x3000>;
				#clock-cells = <0x01>;
				phandle = <0x6b>;
			};
		};

		clock-controller@20200000 {
			compatible = "sprd,ums512-ap-clk";
			reg = <0x00 0x20200000 0x00 0x1000>;
			clocks = <0x1a>;
			clock-names = "ext-26m";
			#clock-cells = <0x01>;
			phandle = <0x4a>;
		};

		dma-controller@20000000 {
			compatible = "sprd,sharkl5pro-dma", "sprd,sc9860-dma";
			reg = <0x00 0x20000000 0x00 0x4000>;
			interrupts = <0x00 0x18 0x04>;
			#dma-cells = <0x01>;
			#dma-channels = <0x1c>;
			clock-names = "enable";
			clocks = <0x48 0x04>;
			status = "disabled";
			phandle = <0xc4>;
		};

		i2s@70c00000 {
			compatible = "unisoc,i2s";
			reg = <0x00 0x70c00000 0x00 0x1000>;
			sprd,dai_name = "i2s_bt_sco0";
			sprd,hw_port = <0x00>;
			sprd,syscon-ap-apb = <0x49>;
			sprd,syscon-agcp-ahb = <0x35>;
			#sound-dai-cells = <0x00>;
			clock-names = "clk_iis0", "clk_twpll_128m", "clk_twpll_153m6";
			clocks = <0x4a 0x0e 0x45 0x0a 0x45 0x0f>;
			status = "disabled";
			phandle = <0xc6>;
		};

		clock-controller@32080000 {
			compatible = "sprd,ums512-aonapb-clk";
			reg = <0x00 0x32080000 0x00 0x1000>;
			clocks = <0x1a 0x4b 0x4c 0x4d>;
			clock-names = "ext-26m", "ext-32k", "ext-4m", "rco-100m";
			#clock-cells = <0x01>;
			phandle = <0x89>;
		};

		clock-controller@62100000 {
			compatible = "sprd,ums512-mm-clk";
			reg = <0x00 0x62100000 0x00 0x1000>;
			clocks = <0x1a 0x4e 0x07>;
			clock-names = "ext-26m", "enable";
			power-domains = <0x43 0x0d>;
			#clock-cells = <0x01>;
		};

		funnel@3c002000 {
			compatible = "arm,coresight-dynamic-funnel", "arm,primecell";
			reg = <0x00 0x3c002000 0x00 0x1000>;
			clocks = <0x1a>;
			clock-names = "apb_pclk";

			out-ports {

				port {

					endpoint {
						remote-endpoint = <0x4f>;
						phandle = <0x51>;
					};
				};
			};

			in-ports {
				#address-cells = <0x01>;
				#size-cells = <0x00>;

				port@1 {
					reg = <0x01>;

					endpoint {
						remote-endpoint = <0x50>;
						phandle = <0x5b>;
					};
				};
			};
		};

		etb@3c003000 {
			compatible = "arm,coresight-tmc", "arm,primecell";
			reg = <0x00 0x3c003000 0x00 0x1000>;
			clocks = <0x1a>;
			clock-names = "apb_pclk";

			in-ports {

				port {

					endpoint {
						remote-endpoint = <0x51>;
						phandle = <0x4f>;
					};
				};
			};
		};

		funnel@3e001000 {
			compatible = "arm,coresight-dynamic-funnel", "arm,primecell";
			reg = <0x00 0x3e001000 0x00 0x1000>;
			clocks = <0x1a>;
			clock-names = "apb_pclk";

			out-ports {

				port {

					endpoint {
						remote-endpoint = <0x52>;
						phandle = <0x58>;
					};
				};
			};

			in-ports {
				#address-cells = <0x01>;
				#size-cells = <0x00>;

				port@0 {
					reg = <0x00>;

					endpoint {
						remote-endpoint = <0x53>;
						phandle = <0x66>;
					};
				};

				port@1 {
					reg = <0x01>;

					endpoint {
						remote-endpoint = <0x54>;
						phandle = <0x67>;
					};
				};

				port@2 {
					reg = <0x02>;

					endpoint {
						remote-endpoint = <0x55>;
						phandle = <0x68>;
					};
				};

				port@3 {
					reg = <0x03>;

					endpoint {
						remote-endpoint = <0x56>;
						phandle = <0x6a>;
					};
				};
			};
		};

		etf@3e002000 {
			compatible = "arm,coresight-tmc", "arm,primecell";
			reg = <0x00 0x3e002000 0x00 0x1000>;
			clocks = <0x1a>;
			clock-names = "apb_pclk";

			out-ports {

				port {

					endpoint {
						remote-endpoint = <0x57>;
						phandle = <0x5c>;
					};
				};
			};

			in-ports {

				port {

					endpoint {
						remote-endpoint = <0x58>;
						phandle = <0x52>;
					};
				};
			};
		};

		etf@3e003000 {
			compatible = "arm,coresight-tmc", "arm,primecell";
			reg = <0x00 0x3e003000 0x00 0x1000>;
			clocks = <0x1a>;
			clock-names = "apb_pclk";

			out-ports {

				port {

					endpoint {
						remote-endpoint = <0x59>;
						phandle = <0x5d>;
					};
				};
			};

			in-ports {

				port {

					endpoint {
						remote-endpoint = <0x5a>;
						phandle = <0x5e>;
					};
				};
			};
		};

		funnel@3e004000 {
			compatible = "arm,coresight-dynamic-funnel", "arm,primecell";
			reg = <0x00 0x3e004000 0x00 0x1000>;
			clocks = <0x1a>;
			clock-names = "apb_pclk";

			out-ports {

				port {

					endpoint {
						remote-endpoint = <0x5b>;
						phandle = <0x50>;
					};
				};
			};

			in-ports {
				#address-cells = <0x01>;
				#size-cells = <0x00>;

				port@0 {
					reg = <0x00>;

					endpoint {
						remote-endpoint = <0x5c>;
						phandle = <0x57>;
					};
				};

				port@1 {
					reg = <0x01>;

					endpoint {
						remote-endpoint = <0x5d>;
						phandle = <0x59>;
					};
				};
			};
		};

		funnel@3e005000 {
			compatible = "arm,coresight-dynamic-funnel", "arm,primecell";
			reg = <0x00 0x3e005000 0x00 0x1000>;
			clocks = <0x1a>;
			clock-names = "apb_pclk";

			out-ports {

				port {

					endpoint {
						remote-endpoint = <0x5e>;
						phandle = <0x5a>;
					};
				};
			};

			in-ports {
				#address-cells = <0x01>;
				#size-cells = <0x00>;

				port@0 {
					reg = <0x00>;

					endpoint {
						remote-endpoint = <0x5f>;
						phandle = <0x63>;
					};
				};

				port@1 {
					reg = <0x01>;

					endpoint {
						remote-endpoint = <0x60>;
						phandle = <0x64>;
					};
				};

				port@2 {
					reg = <0x02>;

					endpoint {
						remote-endpoint = <0x61>;
						phandle = <0x65>;
					};
				};

				port@3 {
					reg = <0x03>;

					endpoint {
						remote-endpoint = <0x62>;
						phandle = <0x69>;
					};
				};
			};
		};

		etm@3f040000 {
			compatible = "arm,coresight-etm4x", "arm,primecell";
			reg = <0x00 0x3f040000 0x00 0x1000>;
			cpu = <0x04>;
			clocks = <0x1a>;
			clock-names = "apb_pclk";

			out-ports {

				port {

					endpoint {
						remote-endpoint = <0x63>;
						phandle = <0x5f>;
					};
				};
			};
		};

		etm@3f140000 {
			compatible = "arm,coresight-etm4x", "arm,primecell";
			reg = <0x00 0x3f140000 0x00 0x1000>;
			cpu = <0x05>;
			clocks = <0x1a>;
			clock-names = "apb_pclk";

			out-ports {

				port {

					endpoint {
						remote-endpoint = <0x64>;
						phandle = <0x60>;
					};
				};
			};
		};

		etm@3f240000 {
			compatible = "arm,coresight-etm4x", "arm,primecell";
			reg = <0x00 0x3f240000 0x00 0x1000>;
			cpu = <0x06>;
			clocks = <0x1a>;
			clock-names = "apb_pclk";

			out-ports {

				port {

					endpoint {
						remote-endpoint = <0x65>;
						phandle = <0x61>;
					};
				};
			};
		};

		etm@3f340000 {
			compatible = "arm,coresight-etm4x", "arm,primecell";
			reg = <0x00 0x3f340000 0x00 0x1000>;
			cpu = <0x07>;
			clocks = <0x1a>;
			clock-names = "apb_pclk";

			out-ports {

				port {

					endpoint {
						remote-endpoint = <0x66>;
						phandle = <0x53>;
					};
				};
			};
		};

		etm@3f440000 {
			compatible = "arm,coresight-etm4x", "arm,primecell";
			reg = <0x00 0x3f440000 0x00 0x1000>;
			cpu = <0x08>;
			clocks = <0x1a>;
			clock-names = "apb_pclk";

			out-ports {

				port {

					endpoint {
						remote-endpoint = <0x67>;
						phandle = <0x54>;
					};
				};
			};
		};

		etm@3f540000 {
			compatible = "arm,coresight-etm4x", "arm,primecell";
			reg = <0x00 0x3f540000 0x00 0x1000>;
			cpu = <0x09>;
			clocks = <0x1a>;
			clock-names = "apb_pclk";

			out-ports {

				port {

					endpoint {
						remote-endpoint = <0x68>;
						phandle = <0x55>;
					};
				};
			};
		};

		etm@3f640000 {
			compatible = "arm,coresight-etm4x", "arm,primecell";
			reg = <0x00 0x3f640000 0x00 0x1000>;
			cpu = <0x0a>;
			clocks = <0x1a>;
			clock-names = "apb_pclk";

			out-ports {

				port {

					endpoint {
						remote-endpoint = <0x69>;
						phandle = <0x62>;
					};
				};
			};
		};

		etm@3f740000 {
			compatible = "arm,coresight-etm4x", "arm,primecell";
			reg = <0x00 0x3f740000 0x00 0x1000>;
			cpu = <0x0b>;
			clocks = <0x1a>;
			clock-names = "apb_pclk";

			out-ports {

				port {

					endpoint {
						remote-endpoint = <0x6a>;
						phandle = <0x56>;
					};
				};
			};
		};

		apb@70000000 {
			compatible = "simple-bus";
			#address-cells = <0x01>;
			#size-cells = <0x01>;
			ranges = <0x00 0x00 0x70000000 0x10000000>;

			serial@0 {
				compatible = "sprd,ums512-uart", "sprd,sc9836-uart";
				reg = <0x00 0x100>;
				interrupts = <0x00 0x02 0x04>;
				clocks = <0x4a 0x0b 0x1a 0x6b 0x0e>;
				status = "okay";
				clock-names = "uart", "source", "enable";
			};

			serial@100000 {
				compatible = "sprd,ums512-uart", "sprd,sc9836-uart";
				reg = <0x100000 0x100>;
				interrupts = <0x00 0x03 0x04>;
				clocks = <0x4a 0x0c 0x1a 0x6b 0x0f>;
				status = "okay";
				clock-names = "uart", "source", "enable";
			};

			i2c@300000 {
				compatible = "sprd,ums512-i2c", "sprd,sc9860-i2c";
				reg = <0x300000 0x100>;
				interrupts = <0x00 0x0b 0x04>;
				clock-frequency = <0x61a80>;
				#address-cells = <0x01>;
				#size-cells = <0x00>;
				clock-names = "enable", "i2c", "source";
				clocks = <0x6b 0x09 0x4a 0x05 0x1a>;
				status = "disabled";
			};

			i2c@400000 {
				compatible = "sprd,ums512-i2c", "sprd,sc9860-i2c";
				reg = <0x400000 0x100>;
				interrupts = <0x00 0x0c 0x04>;
				clock-frequency = <0x61a80>;
				#address-cells = <0x01>;
				#size-cells = <0x00>;
				clock-names = "enable", "i2c", "source";
				clocks = <0x6b 0x0a 0x4a 0x06 0x1a>;
				status = "disabled";
			};

			i2c@500000 {
				compatible = "sprd,ums512-i2c", "sprd,sc9860-i2c";
				reg = <0x500000 0x100>;
				interrupts = <0x00 0x0d 0x04>;
				clock-frequency = <0x61a80>;
				#address-cells = <0x01>;
				#size-cells = <0x00>;
				clock-names = "enable", "i2c", "source";
				clocks = <0x6b 0x0b 0x4a 0x07 0x1a>;
				status = "disabled";
			};

			i2c@600000 {
				compatible = "sprd,ums512-i2c", "sprd,sc9860-i2c";
				reg = <0x600000 0x100>;
				interrupts = <0x00 0x0e 0x04>;
				clock-frequency = <0x61a80>;
				#address-cells = <0x01>;
				#size-cells = <0x00>;
				clock-names = "enable", "i2c", "source";
				clocks = <0x6b 0x0c 0x4a 0x08 0x1a>;
				status = "okay";

				aw88266a@34 {
					compatible = "awinic,aw88266a";
					reg = <0x34>;
					#sound-dai-cells = <0x00>;
					sound-name-prefix = "LU";
					reset-gpios = <0x6c 0x33 0x01>;
					awinic,dev-index = <0x00>;
					sound-channel = <0x00>;
					spin-data = "l l r r";
					phandle = <0xc0>;
				};

				aw88266a@35 {
					compatible = "awinic,aw88266a";
					reg = <0x35>;
					#sound-dai-cells = <0x00>;
					sound-name-prefix = "RD";
					reset-gpios = <0x6c 0x33 0x01>;
					awinic,dev-index = <0x01>;
					sound-channel = <0x01>;
					spin-data = "r r l l";
					phandle = <0xc1>;
				};

				aw88266a@36 {
					compatible = "awinic,aw88266a";
					reg = <0x36>;
					#sound-dai-cells = <0x00>;
					sound-name-prefix = "RU";
					reset-gpios = <0x6c 0x33 0x01>;
					awinic,dev-index = <0x02>;
					sound-channel = <0x01>;
					spin-data = "r l l r";
					phandle = <0xc2>;
				};

				aw88266a@37 {
					compatible = "awinic,aw88266a";
					reg = <0x37>;
					#sound-dai-cells = <0x00>;
					sound-name-prefix = "LD";
					reset-gpios = <0x6c 0x33 0x01>;
					awinic,dev-index = <0x03>;
					sound-channel = <0x00>;
					spin-data = "l r r l";
					phandle = <0xc3>;
				};
			};

			i2c@700000 {
				compatible = "sprd,ums512-i2c", "sprd,sc9860-i2c";
				reg = <0x700000 0x100>;
				interrupts = <0x00 0x0f 0x04>;
				clock-frequency = <0x61a80>;
				#address-cells = <0x01>;
				#size-cells = <0x00>;
				clock-names = "enable", "i2c", "source";
				clocks = <0x6b 0x0d 0x4a 0x09 0x1a>;
				status = "okay";
				pinctrl-names = "default";
				pinctrl-0 = <0x6d 0x6e>;

				charger@3b {
					compatible = "sgmicro,sgm41542";
					reg = <0x3b>;
					interrupt-parent = <0x6c>;
					interrupts = <0x9c 0x08>;
					irq-gpios = <0x6c 0x9c 0x01>;
					pinctrl-names = "default";
					pinctrl-0 = <0x6f 0x70>;
					monitored-battery = <0x71>;
					input-current-limit-microamp = <0x1e8480>;
					input-voltage-limit-microvolt = <0x44aa20>;
					phandle = <0x7f>;

					regulators {

						otg-vbus {
							regulator-name = "usb-otg-vbus";
						};
					};
				};
			};

			mmc@1100000 {
				compatible = "sprd,sdhci-r11";
				reg = <0x1100000 0x1000>;
				interrupts = <0x00 0x13 0x04>;
				clocks = <0x4a 0x13 0x6b 0x16>;
				clock-names = "sdio", "enable";
				assigned-clocks = <0x4a 0x13>;
				assigned-clock-parents = <0x72 0x00>;
				status = "okay";
				bus-width = <0x04>;
				/* Stock Samsung X200XXS6DYG6 & upstream ums512-1h10 UHS-I PHY delays */
				sprd,phy-delay-sd-uhs-sdr104 = <0x7f 0x73 0x72 0x72>;
				sprd,phy-delay-sd-uhs-sdr50 = <0x6e 0x7f 0x01 0x01>;
				sprd,phy-delay-sd-highspeed = <0x7f 0x1a 0x9a 0x9a>;
				sprd,phy-delay-legacy = <0x7f 0x1a 0x9a 0x9a>;
				sd-uhs-sdr104;
				sd-uhs-sdr50;
				no-sdio;
				no-mmc;
				cd-gpios = <0x73 0x13 0x00>;
				vmmc-supply = <0x74>;
				vqmmc-supply = <0x75>;
			};

			mmc@1200000 {
				compatible = "sprd,sdhci-r11";
				reg = <0x1200000 0x1000>;
				interrupts = <0x00 0x14 0x04>;
				clocks = <0x4a 0x14 0x6b 0x17>;
				clock-names = "sdio", "enable";
				assigned-clocks = <0x4a 0x14>;
				assigned-clock-parents = <0x45 0x17>;
				status = "okay";
				bus-width = <0x04>;
				sprd,phy-delay-sd-uhs-sdr104 = <0x7f 0x7a 0x72 0x72>;
				sprd,phy-delay-sd-uhs-sdr50 = <0x7f 0xf7 0xf5 0xf5>;
				sd-uhs-sdr104;
				sd-uhs-sdr50;
				no-sd;
				no-mmc;
				phandle = <0xb4>;
			};

			mmc@1400000 {
				compatible = "sprd,sdhci-r11";
				reg = <0x1400000 0x1000>;
				interrupts = <0x00 0x0a 0x04>;
				clocks = <0x4a 0x15 0x6b 0x19>;
				clock-names = "sdio", "enable";
				assigned-clocks = <0x4a 0x15>;
				assigned-clock-parents = <0x72 0x00>;
				status = "okay";
				vmmc-supply = <0x76>;
				bus-width = <0x08>;
				voltage-ranges = <0xbb8 0xbb8>;
				non-removable;
				cap-mmc-hw-reset;
				sprd,phy-delay-mmc-hs400es = <0x40 0x7f 0x2d 0x2d>;
				sprd,phy-delay-mmc-hs400 = <0x3f 0xdf 0x2f 0x2f>;
				sprd,phy-delay-mmc-hs200 = <0x7f 0xde 0xd4 0xd4>;
				sprd,phy-delay-mmc-ddr52 = <0x3e 0x37 0x24 0x24>;
				sprd,phy-delay-mmc-highspeed = <0x60 0xb7 0x34 0x34>;
				mmc-hs400-enhanced-strobe;
				mmc-hs400-1_8v;
				mmc-hs200-1_8v;
				mmc-ddr-1_8v;
				no-sdio;
				no-sd;
			};

			spi@a00000 {
				compatible = "sprd,sc9860-spi";
				reg = <0xa00000 0x1000>;
				interrupts = <0x00 0x07 0x04>;
				clock-names = "enable", "spi", "source";
				clocks = <0x6b 0x07 0x4a 0x0c 0x45 0x03>;
				#address-cells = <0x01>;
				#size-cells = <0x00>;
				status = "okay";

				touchscreen@0 {
					compatible = "himax,hx83102e";
					reg = <0x00>;
					spi-max-frequency = <0x927c00>;
					spi-cpha;
					spi-cpol;
					/* The pad EXTINT0 carries the touch interrupt and LK leaves it on its
					 * function 0, the asynchronous EIC's line 0 (stock: himax,irq-gpio =
					 * <&eic_async 0>). GPIO 144 is the same pad's function 3 and sees
					 * nothing unless the pad is switched. */
					interrupt-parent = <0xc8>;
					interrupts = <0x00 0x02>;
					reset-gpios = <0x6c 0x91 0x01>;
					vsp-supply = <0x77>;
					vsn-supply = <0x78>;
					touchscreen-size-x = <0x4b0>;
					touchscreen-size-y = <0x780>;
					firmware-name = "himax/hx83102e_ls_hsd_firmware.bin";
				};
			};
		};

		bus@32000000 {
			compatible = "simple-bus";
			#address-cells = <0x01>;
			#size-cells = <0x01>;
			ranges = <0x00 0x00 0x32000000 0x1000000>;

			spi@100000 {
				compatible = "sprd,ums512-adi";
				reg = <0x100000 0x100000>;
				#address-cells = <0x01>;
				#size-cells = <0x00>;
				sprd,hw-channels = <0x02 0x18cc 0x03 0x18cc 0x0d 0x1854 0x0f 0x1874 0x11 0x1844 0x13 0x1844 0x15 0x1864 0x1e 0x1820 0x23 0x19b8 0x27 0x19ac>;

				pmic@0 {
					compatible = "sprd,sc2730";
					reg = <0x00>;
					spi-max-frequency = <0x18cba80>;
					interrupts = <0x00 0xad 0x04>;
					interrupt-controller;
					#interrupt-cells = <0x01>;
					#address-cells = <0x01>;
					#size-cells = <0x00>;
					phandle = <0x79>;

					watchdog@40 {
						compatible = "sprd,sc2730-wdt", "sprd,sc27xx-wdt";
						reg = <0x40>;
					};

					led-controller@180 {
						compatible = "sprd,sc2730-bltc", "sprd,sc2731-bltc";
						reg = <0x180>;
						#address-cells = <0x01>;
						#size-cells = <0x00>;

						led@0 {
							label = "red";
							reg = <0x00>;
						};

						led@1 {
							label = "green";
							reg = <0x01>;
						};

						led@2 {
							label = "blue";
							reg = <0x02>;
						};
					};

					rtc@200 {
						compatible = "sprd,sc2730-rtc", "sprd,sc2731-rtc";
						reg = <0x200>;
						interrupt-parent = <0x79>;
						interrupts = <0x01>;
					};

					gpio@280 {
						compatible = "sprd,sc2730-eic", "sprd,sc2731-eic";
						reg = <0x280>;
						interrupt-parent = <0x79>;
						interrupts = <0x04>;
						gpio-controller;
						#gpio-cells = <0x02>;
						interrupt-controller;
						#interrupt-cells = <0x02>;
						phandle = <0x7c>;
					};

					efuse@300 {
						compatible = "sprd,sc2730-efuse";
						reg = <0x300>;
						#address-cells = <0x01>;
						#size-cells = <0x01>;
						hwlocks = <0x1c 0x0c>;

						pddelta-calib@2 {
							reg = <0x02 0x02>;
							bits = <0x07 0x07>;
							phandle = <0x81>;
						};

						fgu-calib@6 {
							reg = <0x06 0x02>;
							bits = <0x00 0x09>;
							phandle = <0x7e>;
						};

						pdrc-calib@7 {
							reg = <0x07 0x01>;
							bits = <0x01 0x07>;
							phandle = <0x80>;
						};

						typec-calib@1a {
							reg = <0x1a 0x02>;
							phandle = <0x83>;
						};

						pdref-calib@1f {
							reg = <0x1f 0x01>;
							bits = <0x04 0x04>;
							phandle = <0x82>;
						};

						adc-big-scale@24 {
							reg = <0x24 0x02>;
							phandle = <0x7a>;
						};

						adc-small-scale@26 {
							reg = <0x26 0x02>;
							phandle = <0x7b>;
						};

						aud-pabst-vcal@20 {
							reg = <0x20 0x02>;
							phandle = <0x84>;
						};

						neg-cp@22 {
							reg = <0x22 0x02>;
							phandle = <0x85>;
						};

						fgu-4p2@6 {
							reg = <0x06 0x02>;
							phandle = <0x86>;
						};

						codec-product-info@2e {
							reg = <0x2e 0x02>;
							phandle = <0x87>;
						};
					};

					adc@504 {
						compatible = "sprd,sc2730-adc";
						reg = <0x504>;
						interrupt-parent = <0x79>;
						interrupts = <0x00>;
						#io-channel-cells = <0x01>;
						hwlocks = <0x1c 0x04>;
						nvmem-cells = <0x7a 0x7b>;
						nvmem-cell-names = "big_scale_calib", "small_scale_calib";
						phandle = <0x7d>;
					};

					fuel-gauge@c00 {
						compatible = "sprd,sc2730-fgu";
						reg = <0xc00>;
						battery-detect-gpios = <0x7c 0x03 0x00>;
						io-channels = <0x7d 0x00 0x7d 0x0e>;
						io-channel-names = "bat-temp", "charge-vol";
						nvmem-cells = <0x7e>;
						nvmem-cell-names = "fgu_calib";
						interrupt-parent = <0x79>;
						interrupts = <0x03>;
						status = "okay";
						monitored-battery = <0x71>;
						power-supplies = <0x7f>;
						sprd,calib-resistance-micro-ohms = <0x2710>;
					};

					pd@e00 {
						compatible = "sprd,sc2730-pd";
						reg = <0xe00 0x380>;
						interrupt-parent = <0x79>;
						interrupts = <0x09 0x08>;
						nvmem-cells = <0x80 0x81 0x82 0x83 0x83>;
						nvmem-cell-names = "pdrc_calib", "pddelta_calib", "pdref_calib", "typec_cc1_cal", "typec_cc2_cal";
						status = "disabled";
					};

					audio-codec@1000 {
						compatible = "unisoc,sc2730-audio-codec", "sprd,sc2730-audio-codec";
						reg = <0x1000>;
						#sound-dai-cells = <0x01>;
						nvmem-cells = <0x84 0x85 0x86 0x87>;
						nvmem-cell-names = "aud_pabst_vcal_efuse", "neg_cp_efuse", "fgu_4p2_efuse", "codec_product_info";
						status = "okay";
						sprd,syscon-pmu-apb = <0x10>;
						hp-use-inter-pa = <0x01>;
						fixed-sample-rate = <0xbb80 0xbb80 0xbb80>;
						digital-codec = <0x88>;
						phandle = <0xbf>;
					};

					/*
					 * vibrator@1b90 intentionally omitted (Issue #14): SM-X200 has no
					 * vibration motor; PMIC LDO VDDVIB (0x1b90, 3.00 V) powers the
					 * display/touch panel. Never bind sc27xx-vibrator to it.
					 */

					regulators {

						dcdc-cpu {
							regulator-name = "vddcpu";
							regulator-min-microvolt = <0x30d40>;
							regulator-max-microvolt = <0x185dcb>;
							regulator-ramp-delay = <0x61a8>;
							regulator-always-on;
						};

						dcdc-gpu {
							regulator-name = "vddgpu";
							regulator-min-microvolt = <0x30d40>;
							regulator-max-microvolt = <0x185dcb>;
							regulator-ramp-delay = <0x61a8>;
							regulator-always-on;
							phandle = <0x47>;
						};

						dcdc-core {
							regulator-name = "vddcore";
							regulator-min-microvolt = <0x30d40>;
							regulator-max-microvolt = <0x185dcb>;
							regulator-ramp-delay = <0x61a8>;
							regulator-always-on;
						};

						dcdc-modem {
							regulator-name = "vddmodem";
							regulator-min-microvolt = <0x30d40>;
							regulator-max-microvolt = <0x185dcb>;
							regulator-ramp-delay = <0x61a8>;
							regulator-always-on;
						};

						dcdc-mem {
							regulator-name = "vddmem";
							regulator-min-microvolt = <0x61a80>;
							regulator-max-microvolt = <0x185196>;
							regulator-ramp-delay = <0x61a8>;
							regulator-always-on;
						};

						dcdc-memq {
							regulator-name = "vddmemq";
							regulator-min-microvolt = <0x61a80>;
							regulator-max-microvolt = <0x185dcb>;
							regulator-ramp-delay = <0x61a8>;
							regulator-always-on;
						};

						dcdc-gen0 {
							regulator-name = "vddgen0";
							regulator-min-microvolt = <0x129da0>;
							regulator-max-microvolt = <0x24c881>;
							regulator-ramp-delay = <0x61a8>;
							regulator-always-on;
						};

						dcdc-gen1 {
							regulator-name = "vddgen1";
							regulator-min-microvolt = <0xcf850>;
							regulator-max-microvolt = <0x1914e6>;
							regulator-ramp-delay = <0x61a8>;
							regulator-always-on;
						};

						dcdc-sram {
							regulator-name = "vddsram";
							regulator-min-microvolt = <0x30d40>;
							regulator-max-microvolt = <0x185dcb>;
							regulator-ramp-delay = <0x61a8>;
							regulator-always-on;
						};

						ldo-avdd18 {
							regulator-name = "avdd18";
							regulator-min-microvolt = <0x11edd8>;
							regulator-max-microvolt = <0x1b8ac8>;
							regulator-ramp-delay = <0x61a8>;
							regulator-always-on;
						};

						ldo-vddrf18 {
							regulator-name = "vddrf18";
							regulator-min-microvolt = <0x11edd8>;
							regulator-max-microvolt = <0x1b8ac8>;
							regulator-ramp-delay = <0x61a8>;
							regulator-always-on;
						};

						ldo-vddcamio {
							regulator-name = "vddcamio";
							regulator-min-microvolt = <0x124f80>;
							regulator-max-microvolt = <0x1bec70>;
							regulator-ramp-delay = <0x61a8>;
						};

						ldo-vddwcn {
							regulator-name = "vddwcn";
							regulator-min-microvolt = <0xdbba0>;
							regulator-max-microvolt = <0x1c2708>;
							regulator-ramp-delay = <0x61a8>;
							phandle = <0xb5>;
						};

						ldo-vddcamd1 {
							regulator-name = "vddcamd1";
							regulator-min-microvolt = <0xdbba0>;
							regulator-max-microvolt = <0x14d408>;
							regulator-ramp-delay = <0x61a8>;
						};

						ldo-vddcamd0 {
							regulator-name = "vddcamd0";
							regulator-min-microvolt = <0xdbba0>;
							regulator-max-microvolt = <0x14d408>;
							regulator-ramp-delay = <0x61a8>;
						};

						ldo-vddrf1v25 {
							regulator-name = "vddrf1v25";
							regulator-min-microvolt = <0xdbba0>;
							regulator-max-microvolt = <0x14d408>;
							regulator-ramp-delay = <0x61a8>;
							regulator-always-on;
						};

						ldo-avdd12 {
							regulator-name = "avdd12";
							regulator-min-microvolt = <0xdbba0>;
							regulator-max-microvolt = <0x14d408>;
							regulator-ramp-delay = <0x61a8>;
							regulator-always-on;
						};

						ldo-vddcama0 {
							regulator-name = "vddcama0";
							regulator-min-microvolt = <0x124f80>;
							regulator-max-microvolt = <0x393870>;
							regulator-ramp-delay = <0x61a8>;
						};

						ldo-vddcama1 {
							regulator-name = "vddcama1";
							regulator-min-microvolt = <0x124f80>;
							regulator-max-microvolt = <0x393870>;
							regulator-ramp-delay = <0x61a8>;
						};

						ldo-vddcammot {
							regulator-name = "vddcammot";
							regulator-min-microvolt = <0x124f80>;
							regulator-max-microvolt = <0x393870>;
							regulator-ramp-delay = <0x61a8>;
						};

						ldo-vddsim2 {
							regulator-name = "vddsim2";
							regulator-min-microvolt = <0x124f80>;
							regulator-max-microvolt = <0x393870>;
							regulator-ramp-delay = <0x61a8>;
							phandle = <0xb7>;
						};

						ldo-vddemmccore {
							regulator-name = "vddemmccore";
							regulator-min-microvolt = <0x124f80>;
							regulator-max-microvolt = <0x393870>;
							regulator-ramp-delay = <0x61a8>;
							phandle = <0x76>;
						};

						ldo-vddsdcore {
							regulator-name = "vddsdcore";
							regulator-min-microvolt = <0x124f80>;
							regulator-max-microvolt = <0x393870>;
							regulator-ramp-delay = <0x61a8>;
							phandle = <0x74>;
						};

						ldo-vddsdio {
							regulator-name = "vddsdio";
							regulator-min-microvolt = <0x124f80>;
							regulator-max-microvolt = <0x393870>;
							regulator-ramp-delay = <0x61a8>;
							phandle = <0x75>;
						};

						ldo-vdd28 {
							regulator-name = "vdd28";
							regulator-min-microvolt = <0x124f80>;
							regulator-max-microvolt = <0x393870>;
							regulator-ramp-delay = <0x61a8>;
							regulator-always-on;
						};

						ldo-vddwifipa {
							regulator-name = "vddwifipa";
							regulator-min-microvolt = <0x124f80>;
							regulator-max-microvolt = <0x393870>;
							regulator-ramp-delay = <0x61a8>;
							phandle = <0xb6>;
						};

						ldo-vdd18-dcxo {
							regulator-name = "vdd18_dcxo";
							regulator-min-microvolt = <0x124f80>;
							regulator-max-microvolt = <0x393870>;
							regulator-ramp-delay = <0x61a8>;
							regulator-always-on;
						};

						ldo-vddusb33 {
							regulator-name = "vddusb33";
							regulator-min-microvolt = <0x124f80>;
							regulator-max-microvolt = <0x393870>;
							regulator-ramp-delay = <0x61a8>;
							phandle = <0x34>;
						};

						ldo-vddldo0 {
							regulator-name = "vddldo0";
							regulator-min-microvolt = <0x124f80>;
							regulator-max-microvolt = <0x393870>;
							regulator-ramp-delay = <0x61a8>;
						};

						ldo-vddldo1 {
							regulator-name = "vddldo1";
							regulator-min-microvolt = <0x124f80>;
							regulator-max-microvolt = <0x393870>;
							regulator-ramp-delay = <0x61a8>;
						};

						ldo-vddldo2 {
							regulator-name = "vddldo2";
							regulator-min-microvolt = <0x124f80>;
							regulator-max-microvolt = <0x393870>;
							regulator-ramp-delay = <0x61a8>;
						};

						ldo-vddkpled {
							regulator-name = "vddkpled";
							regulator-min-microvolt = <0x124f80>;
							regulator-max-microvolt = <0x393870>;
							regulator-ramp-delay = <0x61a8>;
							phandle = <0xb8>;
						};
					};
				};
			};

			hwspinlock@7f0000 {
				compatible = "sprd,hwspinlock-r3p0";
				reg = <0x7f0000 0x10000>;
				#hwlock-cells = <0x01>;
				clocks = <0x1b 0x19>;
				clock-names = "enable";
				phandle = <0x1c>;
			};

			i2c@60000 {
				compatible = "sprd,sharkl5pro-hw-i2c";
				reg = <0x60000 0x1000>;
				interrupts = <0x00 0x44 0x04>;
				clock-names = "enable", "i2c", "source";
				clocks = <0x1b 0x24 0x89 0x11 0x1a>;
				clock-frequency = <0xf4240>;
				#address-cells = <0x01>;
				#size-cells = <0x00>;
				status = "okay";
			};

			gpio@70000 {
				compatible = "sprd,ums512-gpio", "sprd,sc9860-gpio";
				reg = <0x70000 0x10000>;
				gpio-controller;
				#gpio-cells = <0x02>;
				interrupt-controller;
				#interrupt-cells = <0x02>;
				interrupts = <0x00 0x3d 0x04>;
				phandle = <0x6c>;
			};

			pinctrl@450000 {
				compatible = "sprd,ums512-pinctrl";
				reg = <0x450000 0x3000>;

				vbc-iis3-0 {
					pins = "UMS512_IIS_INF0_SYS_SEL";
					sprd,control = <0x0e>;
					phandle = <0x37>;
				};

				vbc-iism0-0 {
					pins = "UMS512_IIS_INF0_SYS_SEL";
					sprd,control = <0x0f>;
					phandle = <0x38>;
				};

				vbc-iis-to-pad {
					pins = "UMS512_VBC_IIS_INF_SYS_SEL";
					sprd,control = <0x00>;
					phandle = <0x39>;
				};

				vbc-iis-to-aon-usb {
					pins = "UMS512_VBC_IIS_INF_SYS_SEL";
					sprd,control = <0x01>;
					phandle = <0x3a>;
				};

				vbc-iism0-1 {
					pins = "UMS512_IIS_INF1_SYS_SEL";
					sprd,control = <0x0f>;
					phandle = <0x3b>;
				};

				vbc-iism0-3 {
					pins = "UMS512_IIS_INF3_SYS_SEL";
					sprd,control = <0x0f>;
					phandle = <0x3c>;
				};

				vbc-iis0-3 {
					pins = "UMS512_IIS_INF3_SYS_SEL";
					sprd,control = <0x0b>;
					phandle = <0x3d>;
				};

				vbc-iis1-3 {
					pins = "UMS512_IIS_INF3_SYS_SEL";
					sprd,control = <0x0c>;
					phandle = <0x3e>;
				};

				vbc-iis2-3 {
					pins = "UMS512_IIS_INF3_SYS_SEL";
					sprd,control = <0x0d>;
					phandle = <0x3f>;
				};

				vbc-iis3-3 {
					pins = "UMS512_IIS_INF3_SYS_SEL";
					sprd,control = <0x0e>;
					phandle = <0x40>;
				};

				ap-iis0-3 {
					pins = "UMS512_IIS_INF3_SYS_SEL";
					sprd,control = <0x00>;
					phandle = <0x41>;
				};

				i2c4-pin-func {
					pins = "UMS512_SIMCLK2", "UMS512_SIMDA2";
					function = "func2";
					phandle = <0x6d>;
				};

				i2c4-pin-misc {
					pins = "UMS512_SIMCLK2_MISC", "UMS512_SIMDA2_MISC";
					bias-pull-up = <0x125c>;
					phandle = <0x6e>;
				};

				charger-int-func {
					pins = "UMS512_MTCK_ARM";
					function = "func4";
					phandle = <0x6f>;
				};

				charger-int-misc {
					pins = "UMS512_MTCK_ARM_MISC";
					input-enable;
					bias-pull-up = <0x4e20>;
					phandle = <0x70>;
				};
			};

			pwm@260000 {
				compatible = "sprd,ums512-pwm";
				reg = <0x260000 0x10000>;
				clocks = <0x89 0x06 0x1b 0x32 0x89 0x07 0x1b 0x33 0x89 0x08 0x1b 0x34 0x89 0x09 0x1b 0x35>;
				clock-names = "pwm0", "enable0", "pwm1", "enable1", "pwm2", "enable2", "pwm3", "enable3";
				assigned-clocks = <0x89 0x06 0x89 0x07 0x89 0x08 0x89 0x09>;
				assigned-clock-parents = <0x1a 0x1a 0x1a 0x1a>;
				#pwm-cells = <0x02>;
			};

			thermal@200000 {
				compatible = "sprd,ums512-thermal";
				reg = <0x200000 0x10000>;
				#address-cells = <0x01>;
				#size-cells = <0x00>;
				clock-names = "enable";
				clocks = <0x1b 0x20>;
				#thermal-sensor-cells = <0x01>;
				nvmem-cells = <0x8a 0x8b>;
				nvmem-cell-names = "thm_sign_cal", "thm_ratio_cal";
				phandle = <0x9d>;

				sensor@0 {
					reg = <0x00>;
					nvmem-cells = <0x8c>;
					nvmem-cell-names = "sen_delta_cal";
				};

				sensor@1 {
					reg = <0x01>;
					nvmem-cells = <0x8d>;
					nvmem-cell-names = "sen_delta_cal";
				};

				sensor@2 {
					reg = <0x02>;
					nvmem-cells = <0x8e>;
					nvmem-cell-names = "sen_delta_cal";
				};

				sensor@3 {
					reg = <0x03>;
					nvmem-cells = <0x8f>;
					nvmem-cell-names = "sen_delta_cal";
				};

				sensor@4 {
					reg = <0x04>;
					nvmem-cells = <0x90>;
					nvmem-cell-names = "sen_delta_cal";
				};
			};

			thermal@210000 {
				compatible = "sprd,ums512-thermal";
				reg = <0x210000 0x10000>;
				#address-cells = <0x01>;
				#size-cells = <0x00>;
				clock-names = "enable";
				clocks = <0x1b 0x21>;
				#thermal-sensor-cells = <0x01>;
				nvmem-cells = <0x91 0x92>;
				nvmem-cell-names = "thm_sign_cal", "thm_ratio_cal";
				phandle = <0xa1>;

				sensor@0 {
					reg = <0x00>;
					nvmem-cells = <0x93>;
					nvmem-cell-names = "sen_delta_cal";
				};

				sensor@1 {
					reg = <0x01>;
					nvmem-cells = <0x94>;
					nvmem-cell-names = "sen_delta_cal";
				};

				sensor@2 {
					reg = <0x02>;
					nvmem-cells = <0x95>;
					nvmem-cell-names = "sen_delta_cal";
				};

				sensor@3 {
					reg = <0x03>;
					nvmem-cells = <0x96>;
					nvmem-cell-names = "sen_delta_cal";
				};

				sensor@4 {
					reg = <0x04>;
					nvmem-cells = <0x97>;
					nvmem-cell-names = "sen_delta_cal";
				};

				sensor@5 {
					reg = <0x05>;
					nvmem-cells = <0x98>;
					nvmem-cell-names = "sen_delta_cal";
				};
			};

			thermal@220000 {
				compatible = "sprd,ums512-thermal";
				reg = <0x220000 0x10000>;
				#address-cells = <0x01>;
				#size-cells = <0x00>;
				clock-names = "enable";
				clocks = <0x1b 0x22>;
				#thermal-sensor-cells = <0x01>;
				nvmem-cells = <0x99 0x9a>;
				nvmem-cell-names = "thm_sign_cal", "thm_ratio_cal";
				phandle = <0xa7>;

				sensor@0 {
					reg = <0x00>;
					nvmem-cells = <0x9b>;
					nvmem-cell-names = "sen_delta_cal";
				};
			};

			watchdog@2f0000 {
				compatible = "sprd,ums512-wdt", "sprd,sp9860-wdt";
				reg = <0x2f0000 0x10000>;
				interrupts = <0x00 0x4f 0x04>;
				timeout-sec = <0x1e>;
				clock-names = "enable", "rtc_enable";
				clocks = <0x1b 0x37 0x1b 0x41>;
			};
		};

		usb@5fff0000 {
			compatible = "sprd,ums512-musb", "sprd,musb";
			reg = <0x00 0x5fff0000 0x00 0x2000>;
			interrupts = <0x00 0x45 0x04>;
			interrupt-names = "mc";
			clocks = <0x1b 0x17>;
			phys = <0x9c>;
			status = "okay";
			dr_mode = "peripheral";
		};

		thermal-zones {

			cputop0-thermal {
				polling-delay-passive = <0x64>;
				polling-delay = <0x3e8>;
				thermal-sensors = <0x9d 0x00>;

				trips {

					trip-point0 {
						temperature = <0x11170>;
						hysteresis = <0x3e8>;
						type = "passive";
						phandle = <0x9e>;
					};

					cpu-crit {
						temperature = <0x1adb0>;
						hysteresis = <0x7d0>;
						type = "critical";
					};
				};

				cooling-maps {

					map0 {
						trip = <0x9e>;
						cooling-device = <0x04 0xffffffff 0xffffffff>;
					};
				};
			};

			ank0-thermal {
				polling-delay-passive = <0x64>;
				polling-delay = <0x3e8>;
				thermal-sensors = <0x9d 0x03>;

				trips {

					trip-point0 {
						temperature = <0x11170>;
						hysteresis = <0x3e8>;
						type = "passive";
						phandle = <0x9f>;
					};

					cpu-crit {
						temperature = <0x1adb0>;
						hysteresis = <0x7d0>;
						type = "critical";
					};
				};

				cooling-maps {

					map0 {
						trip = <0x9f>;
						cooling-device = <0x04 0xffffffff 0xffffffff>;
					};
				};
			};

			ank1-thermal {
				polling-delay-passive = <0x64>;
				polling-delay = <0x3e8>;
				thermal-sensors = <0x9d 0x04>;

				trips {

					trip-point0 {
						temperature = <0x11170>;
						hysteresis = <0x3e8>;
						type = "passive";
						phandle = <0xa0>;
					};

					cpu-crit {
						temperature = <0x1adb0>;
						hysteresis = <0x7d0>;
						type = "critical";
					};
				};

				cooling-maps {

					map0 {
						trip = <0xa0>;
						cooling-device = <0x04 0xffffffff 0xffffffff>;
					};
				};
			};

			ank2-thermal {
				polling-delay-passive = <0x64>;
				polling-delay = <0x3e8>;
				thermal-sensors = <0xa1 0x01>;

				trips {

					trip-point0 {
						temperature = <0x11170>;
						hysteresis = <0x3e8>;
						type = "passive";
						phandle = <0xa2>;
					};

					cpu-crit {
						temperature = <0x1adb0>;
						hysteresis = <0x7d0>;
						type = "critical";
					};
				};

				cooling-maps {

					map0 {
						trip = <0xa2>;
						cooling-device = <0x04 0xffffffff 0xffffffff>;
					};
				};
			};

			prometheus7-thermal {
				polling-delay-passive = <0x64>;
				polling-delay = <0x3e8>;
				thermal-sensors = <0x9d 0x02>;

				trips {

					trip-point0 {
						temperature = <0x11170>;
						hysteresis = <0x3e8>;
						type = "passive";
						phandle = <0xa3>;
					};

					cpu-crit {
						temperature = <0x1adb0>;
						hysteresis = <0x7d0>;
						type = "critical";
					};
				};

				cooling-maps {

					map0 {
						trip = <0xa3>;
						cooling-device = <0x0a 0xffffffff 0xffffffff>;
					};
				};
			};

			cputop1-thermal {
				polling-delay-passive = <0x64>;
				polling-delay = <0x3e8>;
				thermal-sensors = <0x9d 0x01>;

				trips {

					trip-point0 {
						temperature = <0x11170>;
						hysteresis = <0x3e8>;
						type = "passive";
						phandle = <0xa4>;
					};

					cpu-crit {
						temperature = <0x1adb0>;
						hysteresis = <0x7d0>;
						type = "critical";
					};
				};

				cooling-maps {

					map0 {
						trip = <0xa4>;
						cooling-device = <0x0a 0xffffffff 0xffffffff>;
					};
				};
			};

			gpu-thermal {
				polling-delay-passive = <0x64>;
				polling-delay = <0x3e8>;
				thermal-sensors = <0xa1 0x00>;

				trips {

					trip-point0 {
						temperature = <0x11170>;
						hysteresis = <0x3e8>;
						type = "passive";
						phandle = <0xa5>;
					};

					gpu-crit {
						temperature = <0x1adb0>;
						hysteresis = <0x7d0>;
						type = "critical";
					};
				};

				cooling-maps {

					map0 {
						trip = <0xa5>;
						cooling-device = <0xa6 0xffffffff 0xffffffff>;
					};
				};
			};

			gpuank2-thmzone {
				polling-delay-passive = <0x00>;
				polling-delay = <0x00>;
				thermal-sensors = <0xa7 0x00>;
			};

			ank3-thermal {
				polling-delay-passive = <0x64>;
				polling-delay = <0x3e8>;
				thermal-sensors = <0xa1 0x02>;

				trips {

					trip-point0 {
						temperature = <0x11170>;
						hysteresis = <0x3e8>;
						type = "passive";
						phandle = <0xa8>;
					};

					cpu-crit {
						temperature = <0x1adb0>;
						hysteresis = <0x7d0>;
						type = "critical";
					};
				};

				cooling-maps {

					map0 {
						trip = <0xa8>;
						cooling-device = <0x04 0xffffffff 0xffffffff>;
					};
				};
			};

			ank4-thermal {
				polling-delay-passive = <0x64>;
				polling-delay = <0x3e8>;
				thermal-sensors = <0xa1 0x03>;

				trips {

					trip-point0 {
						temperature = <0x11170>;
						hysteresis = <0x3e8>;
						type = "passive";
						phandle = <0xa9>;
					};

					cpu-crit {
						temperature = <0x1adb0>;
						hysteresis = <0x7d0>;
						type = "critical";
					};
				};

				cooling-maps {

					map0 {
						trip = <0xa9>;
						cooling-device = <0x04 0xffffffff 0xffffffff>;
					};
				};
			};

			ank5-thermal {
				polling-delay-passive = <0x64>;
				polling-delay = <0x3e8>;
				thermal-sensors = <0xa1 0x04>;

				trips {

					trip-point0 {
						temperature = <0x11170>;
						hysteresis = <0x3e8>;
						type = "passive";
						phandle = <0xaa>;
					};

					cpu-crit {
						temperature = <0x1adb0>;
						hysteresis = <0x7d0>;
						type = "critical";
					};
				};

				cooling-maps {

					map0 {
						trip = <0xaa>;
						cooling-device = <0x04 0xffffffff 0xffffffff>;
					};
				};
			};

			prometheus6-thermal {
				polling-delay-passive = <0x64>;
				polling-delay = <0x3e8>;
				thermal-sensors = <0xa1 0x05>;

				trips {

					trip-point0 {
						temperature = <0x11170>;
						hysteresis = <0x3e8>;
						type = "passive";
						phandle = <0xab>;
					};

					cpu-crit {
						temperature = <0x1adb0>;
						hysteresis = <0x7d0>;
						type = "critical";
					};
				};

				cooling-maps {

					map0 {
						trip = <0xab>;
						cooling-device = <0x0a 0xffffffff 0xffffffff>;
					};
				};
			};
		};

		mm {
			compatible = "simple-bus";
			#address-cells = <0x01>;
			#size-cells = <0x01>;
			ranges = <0x20300000 0x00 0x20300000 0x200000>;

			dpu@20300000 {
				compatible = "sprd,ums512-dpu", "sprd,sharkl3-dpu";
				reg = <0x20300000 0x800>;
				interrupts = <0x00 0x1b 0x04>;
				clocks = <0x48 0x01 0x4a 0x17 0x4a 0x18>;
				clock-names = "core", "clk", "dpi";
				iommus = <0xac>;
				status = "okay";
				memory-region = <0xad>;
				reset-syscon = <0xae 0x04 0x02>;
				sprd,dpi-clk-div = <0x06>;
				sprd,qos-syscon = <0xae 0xbc 0xff 0xcf>;
				sprd,dpi-clk-parent = <0xaf>;
				/* AP DVFS work index 4: 384 MHz core clock, 0.75 V (kernel/patches/0002; /init until then) */
				sprd,dvfs-syscon = <0xc7 0x124 0x04>;
				phandle = <0x02>;

				port {
					phandle = <0x0f>;

					endpoint {
						remote-endpoint = <0xb0>;
						phandle = <0xb1>;
					};
				};
			};

			iommu@20300800 {
				compatible = "sprd,ums512-iommu", "sprd,iommu-v1";
				reg = <0x20300800 0x80>;
				sprd,iova-range = <0x90000000 0x10000000>;
				/* Shares DPU AHB gate (CLK_DISPC_EB) across CRTC off / suspend resume */
				clocks = <0x48 0x01>;
				#iommu-cells = <0x00>;
				status = "okay";
				phandle = <0xac>;
			};

			dsi@20400000 {
				compatible = "sprd,ums512-dsi-host", "sprd,ums9230-dsi-host";
				reg = <0x20400000 0x1000>;
				interrupts = <0x00 0x1e 0x04 0x00 0x1f 0x04>;
				clocks = <0x48 0x00>;
				clock-names = "pclk";
				sprd,phy-en-syscon = <0xae 0x40 0x03>;
				sprd,phy-pwr-syscon = <0x49 0x35c 0x08>;
				status = "okay";
				reset-syscon = <0xae 0x04 0x01>;
				#address-cells = <0x01>;
				#size-cells = <0x00>;
				sprd,mipi-drive-capability = <0x05>;
				sprd,dpi-clk-div = <0x06>;

				ports {
					#address-cells = <0x01>;
					#size-cells = <0x00>;

					port@0 {
						reg = <0x00>;

						endpoint {
							remote-endpoint = <0xb1>;
							phandle = <0xb0>;
						};
					};

					port@1 {
						reg = <0x01>;

						endpoint {
							remote-endpoint = <0xb2>;
							phandle = <0xb3>;
						};
					};
				};

				panel@0 {
					compatible = "rocknix,generic-dsi";
					reg = <0x00>;
					reset-gpios = <0x6c 0x32 0x00>;
					vdd-supply = <0x77>;
					iovcc-supply = <0x78>;
					panel_description =
						"G lanes=4 format=rgb888 size=136,225 flags=3 hs_rate=997000000 lp_rate=20000000 delays=1,5,5,60,20",
						"M clock=166159 horizontal=1200,40,12,16 vertical=1920,224,12,28 default=1",
						"I dcs=b9 data=83102e",
						"I dcs=e9 data=cd",
						"I dcs=bb data=01",
						"I dcs=e9 data=00",
						"I dcs=d1 data=670cff05",
						"I dcs=b1 data=10faafaf3131b16b313636363622211500",
						"I dcs=b2 data=00b047800026e0292000000015205700",
						"I dcs=b4 data=6a706a706a906a90019f015800ff00ff",
						"I dcs=d2 data=3131",
						"I dcs=bf data=fc85809c360004",
						"I dcs=d3 data=000000003ce80000003737330f2626040032102400243217a807a8321008000000002b50b6c82c4fb6c80f",
						"I dcs=e0 data=0007131c24425b616660757778837f8892a7a7535b66730007131c24425b616660757778837f8892a7a7535b6673",
						"I dcs=bd data=01",
						"I dcs=cb data=80361216c02854840234",
						"I dcs=d3 data=0100fc00001110000a0001",
						"I dcs=bd data=02",
						"I dcs=b4 data=4e0033113388",
						"I dcs=bf data=f20002",
						"I dcs=bd data=00",
						"I dcs=c0 data=33332211a2170080000008006363",
						"I dcs=d5 data=18181818181818181818191918181a1a1b1b0001020304050607202124251818181818181818181818181818",
						"I dcs=d6 data=18181818181818181818181819191a1a1b1b0706050403020100252421201818181818181818181818181818",
						"I dcs=d0 data=070405",
						"I dcs=e7 data=1213020255000e0e002629721c72012700000000170068",
						"I dcs=bd data=01",
						"I dcs=e7 data=013001940db50e",
						"I dcs=bd data=02",
						"I dcs=e7 data=ff01fd01000022000000000000000000000000000000000081000240",
						"I dcs=bd data=00",
						"I dcs=d8 data=aabbaaaaaaa0aabbaaaaaaa0",
						"I dcs=bd data=01",
						"I dcs=d8 data=fffffffffff0fffffffffff0",
						"I dcs=bd data=02",
						"I dcs=d8 data=fffc3ffffff0fffc3ffffff0",
						"I dcs=bd data=03",
						"I dcs=d8 data=002aaaaaaaa0002aaaaaaaa0002aaaaaaaa0002aaaaaaaa0",
						"I dcs=bd data=00",
						"I dcs=ba data=7003a885f280c00d",
						"I dcs=bd data=03",
						"I dcs=b2 data=80",
						"I dcs=bd data=00",
						"I dcs=c8 data=000404000082",
						"I dcs=bd data=00",
						"I dcs=cb data=0013080225",
						"I dcs=bd data=02",
						"I dcs=cb data=000300017e",
						"I dcs=bd data=00",
						"I dcs=c7 data=3080c208104204",
						"I dcs=e1 data=0005",
						"I dcs=bd data=00",
						"I dcs=cc data=0e",
						"I dcs=51 data=0000",
						"I dcs=c9 data=000e10",
						"I dcs=53 data=2c",
						"I seq=11 wait=32",
						"I seq=29 wait=14",
						"I dcs=b9 data=000000";

					port {

						endpoint {
							remote-endpoint = <0xb3>;
							phandle = <0xb2>;
						};
					};
				};
			};
		};
	};

	clk-26m {
		compatible = "fixed-clock";
		#clock-cells = <0x00>;
		clock-frequency = <0x18cba80>;
		clock-output-names = "ext-26m";
		phandle = <0x1a>;
	};

	dphy-273m {
		compatible = "fixed-clock";
		#clock-cells = <0x00>;
		clock-frequency = <0x1045a640>;
		clock-output-names = "dphy-273m";
		phandle = <0xaf>;
	};

	dphy-204m8 {
		compatible = "fixed-clock";
		#clock-cells = <0x00>;
		clock-frequency = "\f5", "";
		clock-output-names = "dphy-204m8";
	};

	clk-32k {
		compatible = "fixed-clock";
		#clock-cells = <0x00>;
		clock-frequency = <0x8000>;
		clock-output-names = "ext-32k";
		phandle = <0x4b>;
	};

	clk-4m {
		compatible = "fixed-clock";
		#clock-cells = <0x00>;
		clock-frequency = "", "=\t";
		clock-output-names = "ext-4m";
		phandle = <0x4c>;
	};

	clk-100m {
		compatible = "fixed-clock";
		#clock-cells = <0x00>;
		clock-frequency = <0x5f5e100>;
		clock-output-names = "rco-100m";
		phandle = <0x4d>;
	};

	memory@80000000 {
		device_type = "memory";
		reg = <0x00 0x80000000 0x00 0xfffff000>;
	};

	chosen {
		#address-cells = <0x02>;
		#size-cells = <0x02>;
		stdout-path = "serial1:115200n8";
	};

	regulator-lcd-avdd {
		compatible = "regulator-fixed";
		regulator-name = "lcd-avdd";
		gpio = <0x6c 0x8b 0x00>;
		enable-active-high;
		regulator-boot-on;
		regulator-always-on;
		phandle = <0x77>;
	};

	regulator-lcd-avee {
		compatible = "regulator-fixed";
		regulator-name = "lcd-avee";
		gpio = <0x6c 0x8a 0x00>;
		enable-active-high;
		regulator-boot-on;
		regulator-always-on;
		phandle = <0x78>;
	};

	gpio-keys {
		compatible = "gpio-keys";

		key-power {
			label = "Power Key";
			linux,code = <0x74>;
			gpios = <0x7c 0x01 0x01>;
			debounce-interval = <0x02>;
			wakeup-source;
		};

		key-volumedown {
			label = "Volume Down Key";
			linux,code = <0x72>;
			gpios = <0x7c 0x04 0x00>;
			debounce-interval = <0x02>;
		};

		key-volumeup {
			label = "Volume Up Key";
			linux,code = <0x73>;
			gpios = <0x6c 0x7d 0x01>;
			debounce-interval = <0x02>;
		};

		sw-cover {
			label = "Book Cover";
			linux,input-type = <0x05>;
			linux,code = <0x00>;
			gpios = <0x6c 0x54 0x01>;
			debounce-interval = <0x0a>;
		};
	};

	sprd-marlin3 {
		compatible = "unisoc,marlin3lite_sdio";
		enable-gpios = <0x6c 0x8f 0x01>;
		reset-gpios = <0x6c 0x5f 0x01>;
		m2-wakeup-ap-gpios = <0x6c 0x20 0x01>;
		m2-to-ap-irq-gpios = <0x6c 0x5e 0x01>;
		xtal-26m-clk-type = "TSX";
		clock-names = "clk_32k", "source", "enable";
		clocks = <0x89 0x02 0x4b 0x1b 0x03>;
		sdhci-name = <0xb4>;
		adma-tx;
		adma-rx;
		sprd,btwf-file-name = "/lib/firmware/wcnmodem.bin";
		avdd12-supply = <0xb5>;
		avdd33-supply = <0xb6>;
		dcxo18-supply = <0xb7>;
		rfcustom-supply = <0xb8>;
		avdd12-parent-bound-chip = <0x1a4c 0x01 0x00 0x01>;
		avdd12-bound-wbreq = <0x1ac8 0x1000 0x00 0x1000>;
		avdd33-bound-wbreq = <0x1acc 0x04 0x00 0x04>;

		wlan {
			compatible = "sprd,sc2355-sdio-wifi";
			nvmem-cells = <0xb9 0xba>;
			nvmem-cell-names = "uid-start", "uid-end";
		};

		sprd-mtty {
			compatible = "sprd,mtty";
			nvmem-cells = <0xb9 0xba>;
			nvmem-cell-names = "uid-start", "uid-end";
		};
	};

	battery {
		compatible = "simple-battery";
		device-chemistry = "lithium-ion-polymer";
		charge-full-design-microamp-hours = <0x67be98>;
		constant-charge-current-max-microamp = <0x1f20c0>;
		constant-charge-voltage-max-microvolt = <0x42d560>;
		charge-term-current-microamp = <0xfa00>;
		factory-internal-resistance-micro-ohms = <0x18a88>;
		voltage-min-design-microvolt = <0x34bc00>;
		ocv-capacity-celsius = <0x14>;
		ocv-capacity-table-0 = <0x426030 0x64 0x418188 0x5f 0x40a2e0 0x5a 0x3fc820 0x55 0x3ef530 0x50 0x3e2df8 0x4b 0x3d7278 0x46 0x3cca80 0x41 0x3c2288 0x3c 0x3b4f98 0x37 0x3aceb0 0x32 0x3a70f0 0x2d 0x3a22d0 0x28 0x39e838 0x23 0x39b188 0x1e 0x396750 0x19 0x391d18 0x14 0x38bf58 0x0f 0x3851f8 0x0a 0x382700 0x05 0x33e140 0x00>;
		voltage-temp-table = <0x10ec08 0xffffff38 0xf3a70 0xffffff6a 0xd90a8 0xffffff9c 0xbf680 0xffffffce 0xa73c8 0x00 0x91438 0x32 0x7d7d0 0x64 0x6be90 0x96 0x5c878 0xc8 0x4f588 0xfa 0x41eb0 0x12c 0x3a1b0 0x15e 0x31ce0 0x190 0x2ab98 0x1c2 0x24dd8 0x1f4 0x1fbd0 0x226 0x1b580 0x258 0x17ae8 0x28a 0x14820 0x2bc 0x11d28 0x2ee 0xfa00 0x320 0xd6d8 0x352>;
		resistance-temp-table = <0x2d 0x57 0x19 0x64 0x0a 0xf9 0x00 0x359 0xfffffff6 0x4a0 0xffffffec 0x51f>;
		phandle = <0x71>;
	};

	sound@0 {
		compatible = "unisoc,vbc-v4-codec-sc2730";
		status = "okay";
		sprd-audio-card,name = "sprdphone-sc2730";
		sprd-audio-card,routing = "HPMIC Pin", "HP Mic Jack", "MIC Pin", "Mic Jack", "MIC2 Pin", "Aux Mic Jack", "HeadPhone Jack", "HP Pin", "Ext Spk", "SPK Pin", "DMIC Pin", "DMic Jack", "DMIC1 Pin", "DMic1 Jack", "Ext Ear", "EAR Pin";
		sprd,syscon-agcp-ahb = <0x35>;

		sprd-audio-card,dai-link@0 {
			link-name = "FE_NORMAL_AP01";
			stream-name = "FE_ST_NORMAL_AP01";
			ignore-suspend = <0x00>;
			dynamic = <0x01>;
			trigger = <0x01 0x01>;
			dpcm-playback = <0x01>;
			dpcm-capture = <0x01>;
			be-id = <0x00>;

			plat {
				sound-dai = <0xbb>;
			};

			cpu {
				sound-dai = <0xbc 0x00>;
			};

			codec {
				sound-dai = <0x00 0x00>;
			};
		};

		sprd-audio-card,dai-link@1 {
			link-name = "FE_NORMAL_AP23";
			stream-name = "FE_ST_NORMAL_AP23";
			ignore-suspend = <0x00>;
			dynamic = <0x01>;
			trigger = <0x01 0x01>;
			dpcm-playback = <0x01>;
			dpcm-capture = <0x01>;
			be-id = <0x00>;

			plat {
				sound-dai = <0xbb>;
			};

			cpu {
				sound-dai = <0xbc 0x01>;
			};

			codec {
				sound-dai = <0x00 0x00>;
			};
		};

		sprd-audio-card,dai-link@2 {
			link-name = "FE_CAPTURE_DSP";
			stream-name = "FE_ST_CAPTURE_DSP";
			ignore-suspend = <0x01>;
			dynamic = <0x01>;
			trigger = <0x01 0x01>;
			dpcm-capture = <0x01>;
			be-id = <0x00>;

			plat {
				sound-dai = <0xbb>;
			};

			cpu {
				sound-dai = <0xbc 0x02>;
			};

			codec {
				sound-dai = <0x00 0x00>;
			};
		};

		sprd-audio-card,dai-link@3 {
			link-name = "FE_FAST";
			stream-name = "FE_ST_FAST";
			ignore-suspend = <0x01>;
			dynamic = <0x01>;
			trigger = <0x01 0x01>;
			dpcm-playback = <0x01>;
			be-id = <0x00>;

			plat {
				sound-dai = <0xbb>;
			};

			cpu {
				sound-dai = <0xbc 0x03>;
			};

			codec {
				sound-dai = <0x00 0x00>;
			};
		};

		sprd-audio-card,dai-link@5 {
			link-name = "FE_VOICE";
			stream-name = "FE_ST_VOICE";
			ignore-suspend = <0x01>;
			dynamic = <0x01>;
			trigger = <0x01 0x01>;
			dpcm-playback = <0x01>;
			dpcm-capture = <0x01>;
			be-id = <0x00>;

			plat {
				sound-dai = <0xbb>;
			};

			cpu {
				sound-dai = <0xbc 0x05>;
			};

			codec {
				sound-dai = <0x00 0x00>;
			};
		};

		sprd-audio-card,dai-link@6 {
			link-name = "FE_VOIP";
			stream-name = "FE_ST_VOIP";
			ignore-suspend = <0x01>;
			dynamic = <0x01>;
			trigger = <0x01 0x01>;
			dpcm-playback = <0x01>;
			dpcm-capture = <0x01>;
			be-id = <0x00>;

			plat {
				sound-dai = <0xbb>;
			};

			cpu {
				sound-dai = <0xbc 0x06>;
			};

			codec {
				sound-dai = <0x00 0x00>;
			};
		};

		sprd-audio-card,dai-link@7 {
			link-name = "FE_FM";
			stream-name = "FE_ST_FM";
			ignore-suspend = <0x01>;
			dynamic = <0x01>;
			trigger = <0x01 0x01>;
			dpcm-playback = <0x01>;
			be-id = <0x00>;

			plat {
				sound-dai = <0xbb>;
			};

			cpu {
				sound-dai = <0xbc 0x07>;
			};

			codec {
				sound-dai = <0x00 0x00>;
			};
		};

		sprd-audio-card,dai-link@8 {
			link-name = "FE_FM_C";
			stream-name = "FE_ST_FM_C";
			ignore-suspend = <0x01>;
			dynamic = <0x01>;
			trigger = <0x01 0x01>;
			dpcm-capture = <0x01>;
			be-id = <0x00>;

			plat {
				sound-dai = <0xbb>;
			};

			cpu {
				sound-dai = <0xbc 0x08>;
			};

			codec {
				sound-dai = <0x00 0x00>;
			};
		};

		sprd-audio-card,dai-link@9 {
			link-name = "FE_VOICE_C";
			stream-name = "FE_ST_VOICE_C";
			ignore-suspend = <0x01>;
			dynamic = <0x01>;
			trigger = <0x01 0x01>;
			dpcm-capture = <0x01>;
			be-id = <0x00>;

			plat {
				sound-dai = <0xbb>;
			};

			cpu {
				sound-dai = <0xbc 0x09>;
			};

			codec {
				sound-dai = <0x00 0x00>;
			};
		};

		sprd-audio-card,dai-link@10 {
			link-name = "FE_LOOP";
			stream-name = "FE_ST_LOOP";
			ignore-suspend = <0x01>;
			dynamic = <0x01>;
			trigger = <0x01 0x01>;
			dpcm-playback = <0x01>;
			dpcm-capture = <0x01>;
			be-id = <0x00>;

			plat {
				sound-dai = <0xbb>;
			};

			cpu {
				sound-dai = <0xbc 0x0a>;
			};

			codec {
				sound-dai = <0x00 0x00>;
			};
		};

		sprd-audio-card,dai-link@12 {
			link-name = "FE_A2DP_PCM";
			stream-name = "FE_ST_A2DP_PCM";
			ignore-suspend = <0x00>;
			ignore-pmdown-time = <0x00>;
			dynamic = <0x01>;
			trigger = <0x01 0x01>;
			dpcm-playback = <0x01>;
			be-id = <0x00>;

			plat {
				sound-dai = <0xbb>;
			};

			cpu {
				sound-dai = <0xbc 0x0c>;
			};

			codec {
				sound-dai = <0x00 0x00>;
			};
		};

		sprd-audio-card,dai-link@13 {
			link-name = "FE_CAPTURE_FM_DSP";
			stream-name = "FE_ST_CAPTURE_FM_DSP";
			ignore-suspend = <0x01>;
			dynamic = <0x01>;
			trigger = <0x01 0x01>;
			dpcm-capture = <0x01>;
			be-id = <0x00>;

			plat {
				sound-dai = <0xbb>;
			};

			cpu {
				sound-dai = <0xbc 0x0d>;
			};

			codec {
				sound-dai = <0x00 0x00>;
			};
		};

		sprd-audio-card,dai-link@14 {
			link-name = "FE_CAPTURE_BTSCO_DSP";
			stream-name = "FE_ST_CAPTURE_BTSCO_DSP";
			ignore-suspend = <0x01>;
			dynamic = <0x01>;
			trigger = <0x01 0x01>;
			dpcm-capture = <0x01>;
			be-id = <0x00>;

			plat {
				sound-dai = <0xbb>;
			};

			cpu {
				sound-dai = <0xbc 0x0e>;
			};

			codec {
				sound-dai = <0x00 0x00>;
			};
		};

		sprd-audio-card,dai-link@15 {
			link-name = "FE_FM_DSP";
			stream-name = "FE_ST_FM_DSP";
			ignore-suspend = <0x01>;
			dynamic = <0x01>;
			trigger = <0x01 0x01>;
			dpcm-playback = <0x01>;
			be-id = <0x00>;

			plat {
				sound-dai = <0xbb>;
			};

			cpu {
				sound-dai = <0xbc 0x0f>;
			};

			codec {
				sound-dai = <0x00 0x00>;
			};
		};

		sprd-audio-card,dai-link@16 {
			link-name = "FE_DUMP";
			stream-name = "FE_ST_DUMP";
			ignore-suspend = <0x01>;
			dynamic = <0x01>;
			trigger = <0x01 0x01>;
			dpcm-capture = <0x01>;
			be-id = <0x00>;

			plat {
				sound-dai = <0xbb>;
			};

			cpu {
				sound-dai = <0xbc 0x10>;
			};

			codec {
				sound-dai = <0x00 0x00>;
			};
		};

		sprd-audio-card,dai-link@17 {
			link-name = "FE_BTCAP_AP";
			stream-name = "FE_ST_BTCAP_AP";
			ignore-suspend = <0x01>;
			dynamic = <0x01>;
			trigger = <0x01 0x01>;
			dpcm-capture = <0x01>;
			be-id = <0x00>;

			plat {
				sound-dai = <0xbb>;
			};

			cpu {
				sound-dai = <0xbc 0x11>;
			};

			codec {
				sound-dai = <0x00 0x00>;
			};
		};

		sprd-audio-card,dai-link@18 {
			ignore-suspend = <0x00>;
			link-name = "BE_NORMAL_AP01_CODEC";
			stream-name = "BE_ST_NORMAL_AP01_CODEC";
			no-pcm = <0x01>;
			dpcm-playback = <0x01>;
			dpcm-capture = <0x01>;
			be-id = <0x00>;

			plat {
				sound-dai = <0xbd>;
			};

			cpu {
				sound-dai = <0xbe 0x00>;
			};

			codec {
				sound-dai = <0xbf 0x00>;
			};
		};

		sprd-audio-card,dai-link@19 {
			ignore-suspend = <0x00>;
			link-name = "BE_NORMAL_AP23_CODEC";
			stream-name = "BE_ST_NORMAL_AP23_CODEC";
			no-pcm = <0x01>;
			dpcm-playback = <0x01>;
			dpcm-capture = <0x01>;
			be-id = <0x00>;

			plat {
				sound-dai = <0xbd>;
			};

			cpu {
				sound-dai = <0xbe 0x01>;
			};

			codec {
				sound-dai = <0xbf 0x01>;
			};
		};

		sprd-audio-card,dai-link@20 {
			ignore-suspend = <0x00>;
			link-name = "BE_CAPTURE_DSP_CODEC";
			stream-name = "BE_ST_CAPTURE_DSP_CODEC";
			no-pcm = <0x01>;
			dpcm-capture = <0x01>;
			be-id = <0x00>;

			plat {
				sound-dai = <0xbd>;
			};

			cpu {
				sound-dai = <0xbe 0x02>;
			};

			codec {
				sound-dai = <0xbf 0x00>;
			};
		};

		sprd-audio-card,dai-link@21 {
			ignore-suspend = <0x01>;
			link-name = "BE_FAST_CODEC";
			stream-name = "BE_ST_FAST_CODEC";
			no-pcm = <0x01>;
			dpcm-playback = <0x01>;
			be-id = <0x00>;

			plat {
				sound-dai = <0xbd>;
			};

			cpu {
				sound-dai = <0xbe 0x03>;
			};

			codec {
				sound-dai = <0xbf 0x00>;
			};
		};

		sprd-audio-card,dai-link@22 {
			ignore-suspend = <0x00>;
			ignore-pmdown-time = <0x00>;
			link-name = "BE_OFFLOAD_CODEC";
			stream-name = "BE_ST_OFFLOAD_CODEC";
			no-pcm = <0x01>;
			dpcm-playback = <0x01>;
			be-id = <0x00>;

			plat {
				sound-dai = <0xbd>;
			};

			cpu {
				sound-dai = <0xbe 0x04>;
			};

			codec {
				sound-dai = <0xbf 0x00>;
			};
		};

		sprd-audio-card,dai-link@23 {
			ignore-suspend = <0x01>;
			link-name = "BE_VOICE_CODEC";
			stream-name = "BE_ST_VOICE_CODEC";
			no-pcm = <0x01>;
			dpcm-playback = <0x01>;
			dpcm-capture = <0x01>;
			be-id = <0x00>;

			plat {
				sound-dai = <0xbd>;
			};

			cpu {
				sound-dai = <0xbe 0x05>;
			};

			codec {
				sound-dai = <0xbf 0x00>;
			};
		};

		sprd-audio-card,dai-link@24 {
			ignore-suspend = <0x01>;
			link-name = "BE_VOIP_CODEC";
			stream-name = "BE_ST_VOIP_CODEC";
			no-pcm = <0x01>;
			dpcm-playback = <0x01>;
			dpcm-capture = <0x01>;
			be-id = <0x00>;

			plat {
				sound-dai = <0xbd>;
			};

			cpu {
				sound-dai = <0xbe 0x06>;
			};

			codec {
				sound-dai = <0xbf 0x00>;
			};
		};

		sprd-audio-card,dai-link@25 {
			ignore-suspend = <0x01>;
			link-name = "BE_FM_CODEC";
			stream-name = "BE_ST_FM_CODEC";
			no-pcm = <0x01>;
			dpcm-playback = <0x01>;
			be-id = <0x00>;

			plat {
				sound-dai = <0xbd>;
			};

			cpu {
				sound-dai = <0xbe 0x07>;
			};

			codec {
				sound-dai = <0xbf 0x00>;
			};
		};

		sprd-audio-card,dai-link@26 {
			ignore-suspend = <0x01>;
			link-name = "BE_LOOP_CODEC";
			stream-name = "BE_ST_LOOP_CODEC";
			no-pcm = <0x01>;
			dpcm-playback = <0x01>;
			dpcm-capture = <0x01>;
			be-id = <0x00>;

			plat {
				sound-dai = <0xbd>;
			};

			cpu {
				sound-dai = <0xbe 0x08>;
			};

			codec {
				sound-dai = <0xbf 0x00>;
			};
		};

		sprd-audio-card,dai-link@27 {
			ignore-suspend = <0x01>;
			link-name = "BE_FM_DSP_CODEC";
			stream-name = "BE_ST_FM_DSP_CODEC";
			no-pcm = <0x01>;
			dpcm-playback = <0x01>;
			be-id = <0x00>;

			plat {
				sound-dai = <0xbd>;
			};

			cpu {
				sound-dai = <0xbe 0x09>;
			};

			codec {
				sound-dai = <0xbf 0x00>;
			};
		};

		sprd-audio-card,dai-link@28 {
			ignore-suspend = <0x00>;
			link-name = "BE_NORMAL_AP01_USB";
			stream-name = "BE_ST_NORMAL_AP01_USB";
			no-pcm = <0x01>;
			dpcm-playback = <0x01>;
			dpcm-capture = <0x01>;
			be-id = <0x00>;

			plat {
				sound-dai = <0xbd>;
			};

			cpu {
				sound-dai = <0xbe 0x0a>;
			};

			codec {
				sound-dai = <0x00 0x00>;
			};
		};

		sprd-audio-card,dai-link@29 {
			ignore-suspend = <0x00>;
			link-name = "BE_NORMAL_AP23_USB";
			stream-name = "BE_ST_NORMAL_AP23_USB";
			no-pcm = <0x01>;
			dpcm-playback = <0x01>;
			dpcm-capture = <0x01>;
			be-id = <0x00>;

			plat {
				sound-dai = <0xbd>;
			};

			cpu {
				sound-dai = <0xbe 0x0b>;
			};

			codec {
				sound-dai = <0x00 0x00>;
			};
		};

		sprd-audio-card,dai-link@30 {
			ignore-suspend = <0x00>;
			link-name = "BE_CAPTURE_DSP_USB";
			stream-name = "BE_ST_CAPTURE_DSP_USB";
			no-pcm = <0x01>;
			dpcm-capture = <0x01>;
			be-id = <0x00>;

			plat {
				sound-dai = <0xbd>;
			};

			cpu {
				sound-dai = <0xbe 0x0c>;
			};

			codec {
				sound-dai = <0x00 0x00>;
			};
		};

		sprd-audio-card,dai-link@31 {
			ignore-suspend = <0x01>;
			link-name = "BE_FAST_USB";
			stream-name = "BE_ST_FAST_USB";
			no-pcm = <0x01>;
			dpcm-playback = <0x01>;
			be-id = <0x00>;

			plat {
				sound-dai = <0xbd>;
			};

			cpu {
				sound-dai = <0xbe 0x0d>;
			};

			codec {
				sound-dai = <0x00 0x00>;
			};
		};

		sprd-audio-card,dai-link@32 {
			ignore-suspend = <0x00>;
			ignore-pmdown-time = <0x00>;
			link-name = "BE_OFFLOAD_USB";
			stream-name = "BE_ST_OFFLOAD_USB";
			no-pcm = <0x01>;
			dpcm-playback = <0x01>;
			be-id = <0x00>;

			plat {
				sound-dai = <0xbd>;
			};

			cpu {
				sound-dai = <0xbe 0x0e>;
			};

			codec {
				sound-dai = <0x00 0x00>;
			};
		};

		sprd-audio-card,dai-link@33 {
			ignore-suspend = <0x01>;
			link-name = "BE_VOICE_USB";
			stream-name = "BE_ST_VOICE_USB";
			no-pcm = <0x01>;
			dpcm-playback = <0x01>;
			dpcm-capture = <0x01>;
			be-id = <0x00>;

			plat {
				sound-dai = <0xbd>;
			};

			cpu {
				sound-dai = <0xbe 0x0f>;
			};

			codec {
				sound-dai = <0x00 0x00>;
			};
		};

		sprd-audio-card,dai-link@34 {
			ignore-suspend = <0x01>;
			link-name = "BE_VOIP_USB";
			stream-name = "BE_ST_VOIP_USB";
			no-pcm = <0x01>;
			dpcm-playback = <0x01>;
			dpcm-capture = <0x01>;
			be-id = <0x00>;

			plat {
				sound-dai = <0xbd>;
			};

			cpu {
				sound-dai = <0xbe 0x10>;
			};

			codec {
				sound-dai = <0x00 0x00>;
			};
		};

		sprd-audio-card,dai-link@35 {
			ignore-suspend = <0x01>;
			link-name = "BE_FM_USB";
			stream-name = "BE_ST_FM_USB";
			no-pcm = <0x01>;
			dpcm-playback = <0x01>;
			be-id = <0x00>;

			plat {
				sound-dai = <0xbd>;
			};

			cpu {
				sound-dai = <0xbe 0x11>;
			};

			codec {
				sound-dai = <0x00 0x00>;
			};
		};

		sprd-audio-card,dai-link@36 {
			ignore-suspend = <0x01>;
			link-name = "BE_LOOP_USB";
			stream-name = "BE_ST_LOOP_USB";
			no-pcm = <0x01>;
			dpcm-playback = <0x01>;
			dpcm-capture = <0x01>;
			be-id = <0x00>;

			plat {
				sound-dai = <0xbd>;
			};

			cpu {
				sound-dai = <0xbe 0x12>;
			};

			codec {
				sound-dai = <0x00 0x00>;
			};
		};

		sprd-audio-card,dai-link@37 {
			ignore-suspend = <0x01>;
			link-name = "BE_FM_DSP_USB";
			stream-name = "BE_ST_FM_DSP_USB";
			no-pcm = <0x01>;
			dpcm-playback = <0x01>;
			be-id = <0x00>;

			plat {
				sound-dai = <0xbd>;
			};

			cpu {
				sound-dai = <0xbe 0x13>;
			};

			codec {
				sound-dai = <0x00 0x00>;
			};
		};

		sprd-audio-card,dai-link@38 {
			ignore-suspend = <0x00>;
			ignore-pmdown-time = <0x00>;
			link-name = "BE_OFFLOAD_A2DP";
			stream-name = "BE_ST_OFFLOAD_A2DP";
			no-pcm = <0x01>;
			dpcm-playback = <0x01>;
			be-id = <0x00>;

			plat {
				sound-dai = <0xbd>;
			};

			cpu {
				sound-dai = <0xbe 0x14>;
			};

			codec {
				sound-dai = <0x00 0x00>;
			};
		};

		sprd-audio-card,dai-link@39 {
			ignore-suspend = <0x00>;
			ignore-pmdown-time = <0x00>;
			link-name = "BE_PCM_A2DP";
			stream-name = "BE_ST_PCM_A2DP";
			no-pcm = <0x01>;
			dpcm-playback = <0x01>;
			be-id = <0x00>;

			plat {
				sound-dai = <0xbd>;
			};

			cpu {
				sound-dai = <0xbe 0x15>;
			};

			codec {
				sound-dai = <0x00 0x00>;
			};
		};

		sprd-audio-card,dai-link@40 {
			ignore-suspend = <0x01>;
			link-name = "BE_VOICE_BT";
			stream-name = "BE_ST_VOICE_BT";
			no-pcm = <0x01>;
			dpcm-playback = <0x01>;
			dpcm-capture = <0x01>;
			be-id = <0x00>;

			plat {
				sound-dai = <0xbd>;
			};

			cpu {
				sound-dai = <0xbe 0x16>;
			};

			codec {
				sound-dai = <0x00 0x00>;
			};
		};

		sprd-audio-card,dai-link@41 {
			ignore-suspend = <0x01>;
			link-name = "BE_VOIP_BT";
			stream-name = "BE_ST_VOIP_BT";
			no-pcm = <0x01>;
			dpcm-playback = <0x01>;
			dpcm-capture = <0x01>;
			be-id = <0x00>;

			plat {
				sound-dai = <0xbd>;
			};

			cpu {
				sound-dai = <0xbe 0x17>;
			};

			codec {
				sound-dai = <0x00 0x00>;
			};
		};

		sprd-audio-card,dai-link@42 {
			ignore-suspend = <0x01>;
			link-name = "BE_LOOP_BT";
			stream-name = "BE_ST_LOOP_BT";
			no-pcm = <0x01>;
			dpcm-playback = <0x01>;
			dpcm-capture = <0x01>;
			be-id = <0x00>;

			plat {
				sound-dai = <0xbd>;
			};

			cpu {
				sound-dai = <0xbe 0x18>;
			};

			codec {
				sound-dai = <0x00 0x00>;
			};
		};

		sprd-audio-card,dai-link@43 {
			ignore-suspend = <0x01>;
			link-name = "BE_BT_C";
			stream-name = "BE_ST_BT_C";
			no-pcm = <0x01>;
			dpcm-capture = <0x01>;
			be-id = <0x00>;

			plat {
				sound-dai = <0xbd>;
			};

			cpu {
				sound-dai = <0xbe 0x19>;
			};

			codec {
				sound-dai = <0x00 0x00>;
			};
		};

		sprd-audio-card,dai-link@44 {
			ignore-suspend = <0x01>;
			link-name = "BE_VOICE_C";
			stream-name = "BE_ST_VOICE_C";
			no-pcm = <0x01>;
			dpcm-capture = <0x01>;
			be-id = <0x00>;

			plat {
				sound-dai = <0xbd>;
			};

			cpu {
				sound-dai = <0xbe 0x1a>;
			};

			codec {
				sound-dai = <0x00 0x00>;
			};
		};

		sprd-audio-card,dai-link@45 {
			ignore-suspend = <0x01>;
			link-name = "BE_FM_C";
			stream-name = "BE_ST_FM_C";
			no-pcm = <0x01>;
			dpcm-capture = <0x01>;
			be-id = <0x00>;

			plat {
				sound-dai = <0xbd>;
			};

			cpu {
				sound-dai = <0xbe 0x1b>;
			};

			codec {
				sound-dai = <0x00 0x00>;
			};
		};

		sprd-audio-card,dai-link@46 {
			ignore-suspend = <0x00>;
			link-name = "BE_CAPTURE_FM_DSP";
			stream-name = "BE_ST_CAPTURE_FM_DSP";
			no-pcm = <0x01>;
			dpcm-capture = <0x01>;
			be-id = <0x00>;

			plat {
				sound-dai = <0xbd>;
			};

			cpu {
				sound-dai = <0xbe 0x1c>;
			};

			codec {
				sound-dai = <0x00 0x00>;
			};
		};

		sprd-audio-card,dai-link@47 {
			ignore-suspend = <0x00>;
			link-name = "BE_CAPTURE_BTSCO_DSP";
			stream-name = "BE_ST_CAPTURE_BTSCO_DSP";
			no-pcm = <0x01>;
			dpcm-capture = <0x01>;
			be-id = <0x00>;

			plat {
				sound-dai = <0xbd>;
			};

			cpu {
				sound-dai = <0xbe 0x1d>;
			};

			codec {
				sound-dai = <0x00 0x00>;
			};
		};

		sprd-audio-card,dai-link@48 {
			ignore-suspend = <0x01>;
			link-name = "BE_DUMP";
			stream-name = "BE_DUMP";
			no-pcm = <0x01>;
			dpcm-capture = <0x01>;
			be-id = <0x00>;

			plat {
				sound-dai = <0xbd>;
			};

			cpu {
				sound-dai = <0xbe 0x1e>;
			};

			codec {
				sound-dai = <0x00 0x00>;
			};
		};

		sprd-audio-card,dai-link@49 {
			link-name = "FE_TEST_CODEC";
			stream-name = "FE_ST_TEST_CODEC";
			ignore-suspend = <0x00>;
			dynamic = <0x01>;
			trigger = <0x01 0x01>;
			dpcm-playback = <0x01>;
			dpcm-capture = <0x01>;
			be-id = <0x00>;

			plat {
				sound-dai = <0xbb>;
			};

			cpu {
				sound-dai = <0xbc 0x13>;
			};

			codec {
				sound-dai = <0x00 0x00>;
			};
		};

		sprd-audio-card,dai-link@50 {
			ignore-suspend = <0x01>;
			link-name = "BE_TEST_CODEC";
			stream-name = "BE_TEST_CODEC";
			no-pcm = <0x01>;
			dpcm-playback = <0x01>;
			dpcm-capture = <0x01>;
			be-id = <0x00>;

			plat {
				sound-dai = <0xbd>;
			};

			cpu {
				sound-dai = <0xbe 0x1f>;
			};

			codec {
				sound-dai = <0xbf 0x00>;
			};
		};

		sprd-audio-card,dai-link@51 {
			ignore-suspend = <0x01>;
			link-name = "BE_FAST_BTSCO";
			stream-name = "BE_ST_FAST_BTSCO";
			no-pcm = <0x01>;
			dpcm-playback = <0x01>;
			be-id = <0x00>;

			plat {
				sound-dai = <0xbd>;
			};

			cpu {
				sound-dai = <0xbe 0x20>;
			};

			codec {
				sound-dai = <0x00 0x00>;
			};
		};

		sprd-audio-card,dai-link@52 {
			ignore-suspend = <0x01>;
			link-name = "BE_NORMAL_AP01_BTSCO";
			stream-name = "BE_ST_NORMAL_AP01_BTSCO";
			no-pcm = <0x01>;
			dpcm-playback = <0x01>;
			be-id = <0x00>;

			plat {
				sound-dai = <0xbd>;
			};

			cpu {
				sound-dai = <0xbe 0x21>;
			};

			codec {
				sound-dai = <0x00 0x00>;
			};
		};

		sprd-audio-card,dai-link@68 {
			link-name = "FE_VOICE_PCM_P";
			stream-name = "FE_ST_VOICE_PCM_P";
			ignore-suspend = <0x01>;
			dynamic = <0x01>;
			trigger = <0x01 0x01>;
			dpcm-playback = <0x01>;
			be-id = <0x00>;

			plat {
				sound-dai = <0xbb>;
			};

			cpu {
				sound-dai = <0xbc 0x12>;
			};

			codec {
				sound-dai = <0x00 0x00>;
			};
		};

		sprd-audio-card,dai-link@69 {
			ignore-suspend = <0x01>;
			link-name = "BE_VOICE_PCM_P";
			stream-name = "BE_ST_VOICE_PCM_P";
			no-pcm = <0x01>;
			dpcm-playback = <0x01>;
			be-id = <0x00>;

			plat {
				sound-dai = <0xbd>;
			};

			cpu {
				sound-dai = <0xbe 0x2d>;
			};

			codec {
				sound-dai = <0x00 0x00>;
			};
		};

		sprd-audio-card,dai-link@90 {
			link-name = "FE_MM_P";
			stream-name = "FE_ST_MM_P";
			be-id = <0x00>;
			trigger = <0x01 0x01>;
			ignore-suspend = <0x01>;
			dynamic = <0x01>;
			dpcm-playback = <0x01>;

			plat {
				sound-dai = <0xbb>;
			};

			cpu {
				sound-dai = <0xbc 0x19>;
			};

			codec {
				sound-dai = <0x00 0x00>;
			};
		};

		sprd-audio-card,dai-link@91 {
			link-name = "BE_FAST_P_SMART_AMP";
			stream-name = "BE_ST_FAST_P_SMART_AMP";
			be-id = <0x00>;
			ignore-suspend = <0x00>;
			no-pcm = <0x01>;
			dpcm-playback = <0x01>;

			plat {
				sound-dai = <0xbd>;
			};

			cpu {
				sound-dai = <0xbe 0x39>;
			};

			codec {
				sound-dai = <0xbf 0x00>;
			};
		};

		sprd-audio-card,dai-link@100 {
			ignore-suspend = <0x01>;
			link-name = "BE_NORMAL_AP01_SMTPA";
			stream-name = "BE_ST_NORMAL_AP01_SMTPA";
			no-pcm = <0x01>;
			dpcm-playback = <0x01>;
			be-id = <0x00>;
			dai-format = "i2s";
			multi-codecs = <0x04>;

			plat {
				sound-dai = <0xbd>;
			};

			cpu {
				sound-dai = <0xbe 0x2f>;
			};

			codec {
				sound-dai = <0xc0 0xc1 0xc2 0xc3>;
			};
		};

		sprd-audio-card,dai-link@101 {
			ignore-suspend = <0x01>;
			link-name = "BE_NORMAL_AP23_SMTPA";
			stream-name = "BE_ST_NORMAL_AP23_SMTPA";
			no-pcm = <0x01>;
			dpcm-playback = <0x01>;
			be-id = <0x00>;
			dai-format = "i2s";
			multi-codecs = <0x04>;

			plat {
				sound-dai = <0xbd>;
			};

			cpu {
				sound-dai = <0xbe 0x30>;
			};

			codec {
				sound-dai = <0xc0 0xc1 0xc2 0xc3>;
			};
		};

		sprd-audio-card,dai-link@102 {
			ignore-suspend = <0x01>;
			link-name = "BE_FAST_P_SMTPA";
			stream-name = "BE_ST_FAST_P_SMTPA";
			no-pcm = <0x01>;
			dpcm-playback = <0x01>;
			be-id = <0x00>;
			dai-format = "i2s";
			multi-codecs = <0x04>;

			plat {
				sound-dai = <0xbd>;
			};

			cpu {
				sound-dai = <0xbe 0x31>;
			};

			codec {
				sound-dai = <0xc0 0xc1 0xc2 0xc3>;
			};
		};

		sprd-audio-card,dai-link@103 {
			ignore-suspend = <0x01>;
			link-name = "BE_OFFLOAD_SMTPA";
			stream-name = "BE_ST_OFFLOAD_SMTPA";
			no-pcm = <0x01>;
			dpcm-playback = <0x01>;
			be-id = <0x00>;
			dai-format = "i2s";
			multi-codecs = <0x04>;

			plat {
				sound-dai = <0xbd>;
			};

			cpu {
				sound-dai = <0xbe 0x33>;
			};

			codec {
				sound-dai = <0xc0 0xc1 0xc2 0xc3>;
			};
		};

		sprd-audio-card,dai-link@104 {
			ignore-suspend = <0x01>;
			link-name = "BE_VOICE_SMTPA";
			stream-name = "BE_ST_VOICE_SMTPA";
			no-pcm = <0x01>;
			dpcm-playback = <0x01>;
			be-id = <0x00>;
			dai-format = "i2s";
			multi-codecs = <0x04>;

			plat {
				sound-dai = <0xbd>;
			};

			cpu {
				sound-dai = <0xbe 0x34>;
			};

			codec {
				sound-dai = <0xc0 0xc1 0xc2 0xc3>;
			};
		};

		sprd-audio-card,dai-link@105 {
			ignore-suspend = <0x01>;
			link-name = "BE_VOIP_SMTPA";
			stream-name = "BE_ST_VOIP_SMTPA";
			no-pcm = <0x01>;
			dpcm-playback = <0x01>;
			be-id = <0x00>;
			dai-format = "i2s";
			multi-codecs = <0x04>;

			plat {
				sound-dai = <0xbd>;
			};

			cpu {
				sound-dai = <0xbe 0x35>;
			};

			codec {
				sound-dai = <0xc0 0xc1 0xc2 0xc3>;
			};
		};

		sprd-audio-card,dai-link@106 {
			ignore-suspend = <0x01>;
			link-name = "BE_FM_SMTPA";
			stream-name = "BE_ST_FM_SMTPA";
			no-pcm = <0x01>;
			dpcm-playback = <0x01>;
			be-id = <0x00>;
			dai-format = "i2s";
			multi-codecs = <0x04>;

			plat {
				sound-dai = <0xbd>;
			};

			cpu {
				sound-dai = <0xbe 0x36>;
			};

			codec {
				sound-dai = <0xc0 0xc1 0xc2 0xc3>;
			};
		};

		sprd-audio-card,dai-link@107 {
			ignore-suspend = <0x01>;
			link-name = "BE_LOOPBACK_SMTPA";
			stream-name = "BE_ST_LOOP_SMTPA";
			no-pcm = <0x01>;
			dpcm-playback = <0x01>;
			be-id = <0x00>;
			dai-format = "i2s";
			multi-codecs = <0x04>;

			plat {
				sound-dai = <0xbd>;
			};

			cpu {
				sound-dai = <0xbe 0x37>;
			};

			codec {
				sound-dai = <0xc0 0xc1 0xc2 0xc3>;
			};
		};

		sprd-audio-card,dai-link@108 {
			ignore-suspend = <0x01>;
			link-name = "BE_FM_DSP_SMTPA";
			stream-name = "BE_ST_FM_DSP_SMTPA";
			no-pcm = <0x01>;
			dpcm-playback = <0x01>;
			be-id = <0x00>;
			dai-format = "i2s";
			multi-codecs = <0x04>;

			plat {
				sound-dai = <0xbd>;
			};

			cpu {
				sound-dai = <0xbe 0x38>;
			};

			codec {
				sound-dai = <0xc0 0xc1 0xc2 0xc3>;
			};
		};
	};

	sprd-pcm-iis {
		compatible = "unisoc,sharkl5-pcm-platform";
		#sound-dai-cells = <0x00>;
		dmas = <0xc4 0x04 0xc4 0x03>;
		dma-names = "iis0_tx", "iis0_rx";
		sprd,dma-2stage-usecase = <0x02>;
		sprd,node-count-2stage-level-1 = <0x01>;
		sprd,syscon-pmu-apb = <0x10>;
		sprd,dma-2stage-level-1-int-source = <0x01>;
		phandle = <0xc5>;
	};

	sound@1 {
		compatible = "unisoc,i2s-null-codec";
		status = "disabled";
		sprd-audio-card,name = "all-i2s";

		sprd-audio-card,dai-link@0 {

			plat {
				sound-dai = <0xc5>;
			};

			cpu {
				sound-dai = <0xc6>;
			};

			codec {
				sound-dai = <0x00 0x00>;
			};
		};
	};
};
